VERSION ""

NS_ :

BS_:

BU_: XXX t _ e f S c a I i

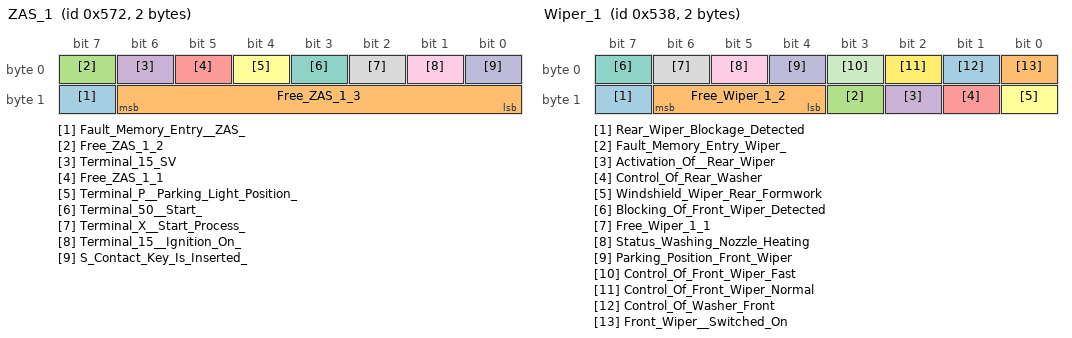
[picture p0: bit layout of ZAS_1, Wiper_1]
BO_ 1394 ZAS_1: 2 XXX
 SG_ Fault_Memory_Entry__ZAS_ : 15|1@1+ (1,0) [0|0] "" XXX
 SG_ Free_ZAS_1_3 : 8|7@1+ (1,0) [0|0] "" XXX
 SG_ Free_ZAS_1_2 : 7|1@1+ (1,0) [0|0] "" XXX
 SG_ Terminal_15_SV : 6|1@1+ (1,0) [0|0] "" XXX
 SG_ Free_ZAS_1_1 : 5|1@1+ (1,0) [0|0] "" XXX
 SG_ Terminal_P__Parking_Light_Position_ : 4|1@1+ (1,0) [0|0] "" XXX
 SG_ Terminal_50__Start_ : 3|1@1+ (1,0) [0|0] "" XXX
 SG_ Terminal_X__Start_Process_ : 2|1@1+ (1,0) [0|0] "" XXX
 SG_ Terminal_15__Ignition_On_ : 1|1@1+ (1,0) [0|0] "" XXX
 SG_ S_Contact_Key_Is_Inserted_ : 0|1@1+ (1,0) [0|0] "" XXX

BO_ 1336 Wiper_1: 2 XXX
 SG_ Rear_Wiper_Blockage_Detected : 15|1@1+ (1,0) [0|0] "" XXX
 SG_ Free_Wiper_1_2 : 12|3@1+ (1,0) [0|0] "" XXX
 SG_ Fault_Memory_Entry_Wiper_ : 11|1@1+ (1,0) [0|0] "" XXX
 SG_ Activation_Of__Rear_Wiper : 10|1@1+ (1,0) [0|0] "" XXX
 SG_ Control_Of_Rear_Washer : 9|1@1+ (1,0) [0|0] "" XXX
 SG_ Windshield_Wiper_Rear_Formwork : 8|1@1+ (1,0) [0|0] "" XXX
 SG_ Blocking_Of_Front_Wiper_Detected : 7|1@1+ (1,0) [0|0] "" XXX
 SG_ Free_Wiper_1_1 : 6|1@1+ (1,0) [0|0] "" XXX
 SG_ Status_Washing_Nozzle_Heating : 5|1@1+ (1,0) [0|0] "" XXX
 SG_ Parking_Position_Front_Wiper : 4|1@1+ (1,0) [0|0] "" XXX
 SG_ Control_Of_Front_Wiper_Fast : 3|1@1+ (1,0) [0|0] "" XXX
 SG_ Control_Of_Front_Wiper_Normal : 2|1@1+ (1,0) [0|0] "" XXX
 SG_ Control_Of_Washer_Front : 1|1@1+ (1,0) [0|0] "" XXX
 SG_ Front_Wiper__Switched_On : 0|1@1+ (1,0) [0|0] "" XXX

BO_ 1464 Immobilizer_1: 2 XXX
 SG_ Immobilizer_Textbits : 8|8@1+ (1,0) [0|0] "" XXX
 SG_ Free_Immobilizer_1_1 : 1|7@1+ (1,0) [0|0] "" XXX
 SG_ Immobilizer_LED : 0|1@1+ (1,0) [0|0] "" XXX

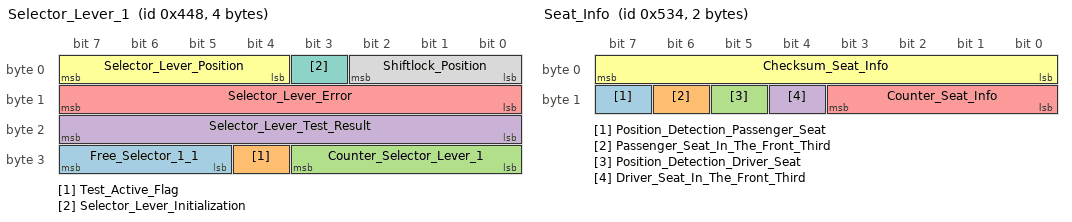
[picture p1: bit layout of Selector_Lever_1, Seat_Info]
BO_ 1096 Selector_Lever_1: 4 XXX
 SG_ Free_Selector_1_1 : 29|3@1+ (1,0) [0|0] "" XXX
 SG_ Test_Active_Flag : 28|1@1+ (1,0) [0|0] "" XXX
 SG_ Counter_Selector_Lever_1 : 24|4@1+ (1,0) [0|15] "" XXX
 SG_ Selector_Lever_Test_Result : 16|8@1+ (1,0) [0|255] "" XXX
 SG_ Selector_Lever_Error : 8|8@1+ (1,0) [0|0] "" XXX
 SG_ Selector_Lever_Position : 4|4@1+ (1,0) [0|0] "" XXX
 SG_ Selector_Lever_Initialization : 3|1@1+ (1,0) [0|0] "" XXX
 SG_ Shiftlock_Position : 0|3@1+ (1,0) [0|0] "" XXX

BO_ 1496 Installation_List_1: 8 XXX
 SG_ TV_Tuner : 63|1@1+ (1,0) [0|0] "" XXX
 SG_ DSP : 62|1@1+ (1,0) [0|0] "" XXX
 SG_ CD_Changer : 61|1@1+ (1,0) [0|0] "" XXX
 SG_ Voice_Input : 60|1@1+ (1,0) [0|0] "" XXX
 SG_ Telematics : 59|1@1+ (1,0) [0|0] "" XXX
 SG_ Navigation : 58|1@1+ (1,0) [0|0] "" XXX
 SG_ Phone : 57|1@1+ (1,0) [0|0] "" XXX
 SG_ Radio : 56|1@1+ (1,0) [0|0] "" XXX
 SG_ Multi_Media_In_Front : 55|1@1+ (1,0) [0|0] "" XXX
 SG_ Multi_Media_In_Rear : 54|1@1+ (1,0) [0|0] "" XXX
 SG_ Free_Installation_List_1_11 : 53|1@1+ (1,0) [0|0] "" XXX
 SG_ Air_Conditioning_Control_Unit_HL : 52|1@1+ (1,0) [0|0] "" XXX
 SG_ Free_Installation_List_1_10 : 50|2@1+ (1,0) [0|0] "" XXX
 SG_ Tank_Sensor : 49|1@1+ (1,0) [0|0] "" XXX
 SG_ Assistant_Driving_Lights : 48|1@1+ (1,0) [0|0] "" XXX
 SG_ Memory_Behind_Driver : 47|1@1+ (1,0) [0|0] "" XXX
 SG_ Seat_Memory_In_The_Back : 46|1@1+ (1,0) [0|0] "" XXX
 SG_ Seat_Memory_Passenger : 45|1@1+ (1,0) [0|0] "" XXX
 SG_ Trailer_Control_Unit : 44|1@1+ (1,0) [0|0] "" XXX
 SG_ Energy_Management : 43|1@1+ (1,0) [0|0] "" XXX
 SG_ Wiper_Module : 42|1@1+ (1,0) [0|0] "" XXX
 SG_ EZS___Kessy__Comfort_ : 41|1@1+ (1,0) [0|0] "" XXX
 SG_ Convertable_Top_Control : 40|1@1+ (1,0) [0|0] "" XXX
 SG_ Heater : 39|1@1+ (1,0) [0|0] "" XXX
 SG_ Free_Installation_List_1_9 : 38|1@1+ (1,0) [0|0] "" XXX
 SG_ Parking_Aid : 37|1@1+ (1,0) [0|0] "" XXX
 SG_ Air_Conditioning_Control_Unit_Comfort : 36|1@1+ (1,0) [0|0] "" XXX
 SG_ Gateway : 35|1@1+ (1,0) [0|0] "" XXX
 SG_ Steering_Column_Module : 34|1@1+ (1,0) [0|0] "" XXX
 SG_ Tire_Pressure : 33|1@1+ (1,0) [0|0] "" XXX
 SG_ Instrument_Cluster_Comfort : 32|1@1+ (1,0) [0|0] "" XXX
 SG_ Roof_Module : 31|1@1+ (1,0) [0|0] "" XXX
 SG_ Memory : 30|1@1+ (1,0) [0|0] "" XXX
 SG_ TSG_HR : 29|1@1+ (1,0) [0|0] "" XXX
 SG_ TSG_HL : 28|1@1+ (1,0) [0|0] "" XXX
 SG_ TSG_BT : 27|1@1+ (1,0) [0|0] "" XXX
 SG_ TSG_FT : 26|1@1+ (1,0) [0|0] "" XXX
 SG_ ZKE : 25|1@1+ (1,0) [0|0] "" XXX
 SG_ BSG_Comfort : 24|1@1+ (1,0) [0|0] "" XXX
 SG_ Free_Installation_List_1_8 : 19|5@1+ (1,0) [0|0] "" XXX
 SG_ Stable_Decoupling : 18|1@1+ (1,0) [0|0] "" XXX
 SG_ Selector_Lever : 17|1@1+ (1,0) [0|0] "" XXX
 SG_ Battery_Manager : 16|1@1+ (1,0) [0|0] "" XXX
 SG_ Damper_SG : 15|1@1+ (1,0) [0|0] "" XXX
 SG_ Leveling : 14|1@1+ (1,0) [0|0] "" XXX
 SG_ EZS___Kessy__Drive_ : 13|1@1+ (1,0) [0|0] "" XXX
 SG_ Brake_Booster : 12|1@1+ (1,0) [0|0] "" XXX
 SG_ Power_Steering : 11|1@1+ (1,0) [0|0] "" XXX
 SG_ Station_Wagon_Drive : 10|1@1+ (1,0) [0|0] "" XXX
 SG_ Injection_Pump : 9|1@1+ (1,0) [0|0] "" XXX
 SG_ Steering_Angle : 8|1@1+ (1,0) [0|0] "" XXX
 SG_ Four_Wheel : 7|1@1+ (1,0) [0|0] "" XXX
 SG_ BSG_Drive : 6|1@1+ (1,0) [0|0] "" XXX
 SG_ ADR : 5|1@1+ (1,0) [0|0] "" XXX
 SG_ Airbag : 4|1@1+ (1,0) [0|0] "" XXX
 SG_ Climatronic_Drive : 3|1@1+ (1,0) [0|0] "" XXX
 SG_ ABS : 2|1@1+ (1,0) [0|0] "" XXX
 SG_ Gearbox_Control_Unit : 1|1@1+ (1,0) [0|0] "" XXX
 SG_ Engine_Control_Unit : 0|1@1+ (1,0) [0|0] "" XXX

BO_ 1488 Systeminfo_1: 6 XXX
 SG_ CAN_Stand_4_1_Drive_Data_Hau : 44|4@1+ (1,0) [0|15] "" XXX
 SG_ CAN_Stand_4_1_Drive_Data_Neb : 40|4@1+ (1,0) [0|15] "" XXX
 SG_ CAN_Stand_4_1_Comfort_Data_Hau : 36|4@1+ (1,0) [0|15] "" XXX
 SG_ CAN_Stand_4_1_Comfort_Data_Neb : 32|4@1+ (1,0) [0|15] "" XXX
 SG_ Free_System_Info_1_6 : 30|1@1+ (1,0) [0|0] "" XXX
 SG_ Four_Day : 29|1@1+ (1,0) [0|0] "" XXX
 SG_ Right_Hand_Drive : 28|1@1+ (1,0) [0|0] "" XXX
 SG_ Vehicle_Index : 24|4@1+ (1,0) [0|0] "" XXX
 SG_ Vehicle_Generation : 20|4@1+ (1,0) [0|15] "" XXX
 SG_ Vehicle_Derivative : 16|4@1+ (1,0) [0|15] "" XXX
 SG_ Vehicle_Brand_2 : 12|4@1+ (1,0) [0|15] "" XXX
 SG_ Vehicle_Class : 8|4@1+ (1,0) [0|15] "" XXX
 SG_ Installation_Information_Valid : 7|1@1+ (1,0) [0|0] "" XXX
 SG_ CAN_Infotainment_Installed : 6|1@1+ (1,0) [0|0] "" XXX
 SG_ CAN_Infotainment_In_Diagnosis : 5|1@1+ (1,0) [0|0] "" XXX
 SG_ Sleep_CAN_Infotainment : 4|1@1+ (1,0) [0|0] "" XXX
 SG_ CAN_Comfort_In_Diagnosis : 3|1@1+ (1,0) [0|0] "" XXX
 SG_ Sleep_CAN_Comfort : 2|1@1+ (1,0) [0|0] "" XXX
 SG_ CAN_Drive_in_Diagnose : 1|1@1+ (1,0) [0|0] "" XXX
 SG_ CAN_External_Connected : 0|1@1+ (1,0) [0|0] "" XXX

BO_ 268 Slave_1: 8 XXX
 SG_ Delta_Reduced_Target_Torque : 48|1@1+ (1,0) [0|0] "" XXX
 SG_ Delta_Throttle_Angle : 32|16@1+ (1,0) [0|0] "" XXX
 SG_ Free_Slave_1_1 : 25|7@1+ (1,0) [0|0] "" XXX
 SG_ Delta_Firing_Angle_Output : 24|1@1+ (1,0) [0|0] "" XXX
 SG_ Ubat_Freigabe_DVE__Slave_ : 23|1@1+ (1,0) [0|0] "" XXX
 SG_ Throttle_Valve_Setpoint_Limitation : 22|1@1+ (1,0) [0|0] "" XXX
 SG_ Injection_Ban_Learn_Slave : 21|1@1+ (1,0) [0|0] "" XXX
 SG_ Master_Recognized__Slave_ : 20|1@1+ (1,0) [0|0] "" XXX
 SG_ Moment_Output_Error : 19|1@1+ (1,0) [0|0] "" XXX
 SG_ Gearbox_Torque_Error : 18|1@1+ (1,0) [0|0] "" XXX
 SG_ Brake_Message_Error : 17|1@1+ (1,0) [0|0] "" XXX
 SG_ Indexed_Actual_Torque_Slave : 0|16@1+ (0.0015259,0) [0|99.998] "%" XXX
 SG_ Brake_Message_Timeout : 0|1@1+ (1,0) [0|0] "" XXX

BO_ 1332 Seat_Info: 2 XXX
 SG_ Position_Detection_Passenger_Seat : 15|1@1+ (1,0) [0|0] "" XXX
 SG_ Passenger_Seat_In_The_Front_Third : 14|1@1+ (1,0) [0|0] "" XXX
 SG_ Position_Detection_Driver_Seat : 13|1@1+ (1,0) [0|0] "" XXX
 SG_ Driver_Seat_In_The_Front_Third : 12|1@1+ (1,0) [0|0] "" XXX
 SG_ Counter_Seat_Info : 8|4@1+ (1,0) [0|15] "" XXX
 SG_ Checksum_Seat_Info : 0|8@1+ (1,0) [0|0] "" XXX

BO_ 1810 PSG_3: 2 XXX
 SG_ Self_Test_Result : 0|16@1+ (1,0) [0|0] "" XXX

BO_ 1298 PSG_2: 8 XXX
 SG_ RAM_Content_4 : 48|16@1+ (1,0) [0|0] "" XXX
 SG_ RAM_Content_3 : 32|16@1+ (1,0) [0|0] "" XXX
 SG_ RAM_Content_2 : 16|16@1+ (1,0) [0|0] "" XXX
 SG_ RAM_Content_1 : 0|16@1+ (1,0) [0|0] "" XXX

BO_ 274 PSG_1: 8 XXX
 SG_ Pump_Temperature__2_1_ : 48|16@1+ (0.0625,0) [0|4096] "K" XXX
 SG_ Pump_Temperature__3_2_2_ : 44|12@1+ (1,0) [0|0] "" XXX
 SG_ Cylinder_Counter__3_2_2_ : 43|3@1+ (1,0) [1|8] "Zaehler" XXX
 SG_ Control_Period__3_2_2_ : 32|11@1+ (0.0469,0) [0|96] "NW" XXX
 SG_ Camshaft_Speed__3_2_2_ : 20|12@1+ (4,0) [0|16380] "upm" XXX
 SG_ Pump_Status : 0|20@1+ (1,0) [0|0] "" XXX

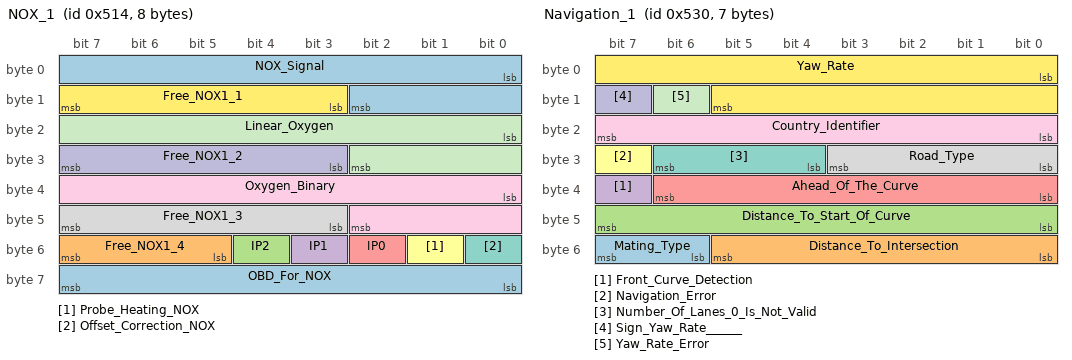
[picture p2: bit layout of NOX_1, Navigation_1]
BO_ 1300 NOX_1: 8 XXX
 SG_ OBD_For_NOX : 56|8@1+ (1,0) [0|0] "" XXX
 SG_ Free_NOX1_4 : 53|3@1+ (1,0) [0|0] "" XXX
 SG_ IP2 : 52|1@1+ (1,0) [0|0] "" XXX
 SG_ IP1 : 51|1@1+ (1,0) [0|0] "" XXX
 SG_ IP0 : 50|1@1+ (1,0) [0|0] "" XXX
 SG_ Probe_Heating_NOX : 49|1@1+ (1,0) [0|0] "" XXX
 SG_ Offset_Correction_NOX : 48|1@1+ (1,0) [0|0] "" XXX
 SG_ Free_NOX1_3 : 43|5@1+ (1,0) [0|0] "" XXX
 SG_ Oxygen_Binary : 32|11@1+ (1,-200) [-200|1847] "mV" XXX
 SG_ Free_NOX1_2 : 27|5@1+ (1,0) [0|0] "" XXX
 SG_ Linear_Oxygen : 16|11@1+ (1,0) [0|2047] "1000/Lambd" XXX
 SG_ Free_NOX1_1 : 11|5@1+ (1,0) [0|0] "" XXX
 SG_ NOX_Signal : 0|11@1+ (1,0) [0|2047] "ppm" XXX

BO_ 1424 Level_1: 6 XXX
 SG_ Loading_Condition : 40|8@1+ (1,0) [0|253] "Zuladung" XXX
 SG_ Fault_Memory_Entry_Level__1 : 39|1@1+ (1,0) [0|0] "" XXX
 SG_ System_Status_Level_1 : 38|1@1+ (1,0) [0|0] "" XXX
 SG_ Reserve_Vehicle_Type : 37|1@1+ (1,0) [0|0] "" XXX
 SG_ Vehicle_Type_Level : 36|1@1+ (1,0) [0|0] "" XXX
 SG_ Text_Bits_Level_1 : 32|4@1+ (1,0) [0|0] "" XXX
 SG_ HL_Adjustment : 31|1@1+ (1,0) [0|0] "" XXX
 SG_ HR_Adjustment : 30|1@1+ (1,0) [0|0] "" XXX
 SG_ VL_Adjustment : 29|1@1+ (1,0) [0|0] "" XXX
 SG_ VR_Adjustment : 28|1@1+ (1,0) [0|0] "" XXX
 SG_ Lowering_Vehicle : 27|1@1+ (1,0) [0|0] "" XXX
 SG_ Raising_Vehicle : 26|1@1+ (1,0) [0|0] "" XXX
 SG_ Adjustment_Active : 25|1@1+ (1,0) [0|0] "" XXX
 SG_ Compressor_Run_Shortly : 24|1@1+ (1,0) [0|0] "" XXX
 SG_ Free_Level_1_5 : 23|1@1+ (1,0) [0|0] "" XXX
 SG_ Push_Button_Level : 22|1@1+ (1,0) [0|0] "" XXX
 SG_ Park_Level : 21|1@1+ (1,0) [0|0] "" XXX
 SG_ Intermediate_Level : 20|1@1+ (1,0) [0|0] "" XXX
 SG_ Static_Level : 16|4@1+ (1,0) [0|0] "" XXX
 SG_ MSG_Restriction : 15|1@1+ (1,0) [0|0] "" XXX
 SG_ ESP_Influence : 14|1@1+ (1,0) [0|0] "" XXX
 SG_ Warning_Lamp_Level_1 : 13|1@1+ (1,0) [0|0] "" XXX
 SG_ Free_Level_1_1 : 12|1@1+ (1,0) [0|0] "" XXX
 SG_ Level_1_Counter : 8|4@1+ (1,0) [0|15] "Zaehler" XXX
 SG_ Checksum_Level_1 : 0|8@1+ (1,0) [0|0] "" XXX

BO_ 1328 Navigation_1: 7 XXX
 SG_ Mating_Type : 54|2@1+ (1,0) [0|3] "" XXX
 SG_ Distance_To_Intersection : 48|6@1+ (5,0) [0|315] "m" XXX
 SG_ Distance_To_Start_Of_Curve : 40|8@1+ (1,0) [0|255] "m" XXX
 SG_ Front_Curve_Detection : 39|1@1+ (1,0) [0|0] "" XXX
 SG_ Ahead_Of_The_Curve : 32|7@1+ (50,0) [0|6350] "m" XXX
 SG_ Navigation_Error : 31|1@1+ (1,0) [0|0] "" XXX
 SG_ Number_Of_Lanes_0_Is_Not_Valid : 28|3@1+ (1,0) [1|7] "" XXX
 SG_ Road_Type : 24|4@1+ (1,0) [0|15] "" XXX
 SG_ Country_Identifier : 16|8@1+ (1,0) [0|0] "" XXX
 SG_ Sign_Yaw_Rate______ : 15|1@1+ (1,0) [0|0] "" XXX
 SG_ Yaw_Rate_Error : 14|1@1+ (1,0) [0|0] "" XXX
 SG_ Yaw_Rate : 0|14@1+ (0.01,0) [0|100] "deg/sek" XXX

BO_ 1792 MSG_3: 3 XXX
 SG_ MSG_Configuration : 16|8@1+ (1,0) [0|0] "" XXX
 SG_ Location_Of_The_OT_Pulse : 0|16@1+ (0.01172,-384) [-384|384] "KW" XXX

BO_ 1280 MSG_2: 8 XXX
 SG_ RAM_Address_4 : 48|16@1+ (1,0) [0|0] "" XXX
 SG_ RAM_Address_3 : 32|16@1+ (1,0) [0|0] "" XXX
 SG_ RAM_Address_2 : 16|16@1+ (1,0) [0|0] "" XXX
 SG_ Ram_Address_1 : 0|16@1+ (1,0) [0|0] "" XXX

BO_ 256 MSG_1: 8 XXX
 SG_ Crankshaft_Speed__3_2_2_ : 56|8@1+ (1,0) [0|0] "" XXX
 SG_ Should_Funding_Start_KW__3_2_2_ : 40|16@1+ (0.01172,-384) [-384|384] "KW" XXX
 SG_ Should_Funding_Start_NW__3_2_2_ : 28|12@1+ (0.01172,0) [0|768] "degNW" XXX
 SG_ Should_Be_Preinjection : 16|12@1+ (1,0) [0|0] "" XXX
 SG_ Target_Injection_Quantity : 0|16@1+ (0.03125,0) [0|2047] "mg/H" XXX

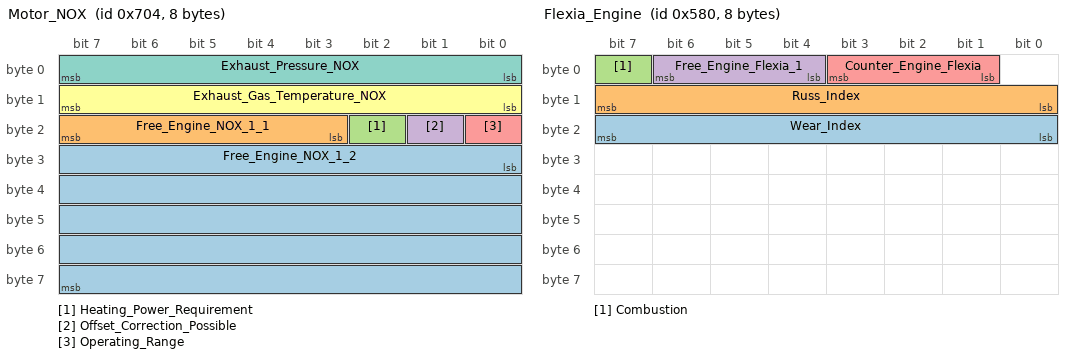
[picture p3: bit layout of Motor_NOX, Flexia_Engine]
BO_ 1796 Motor_NOX: 8 XXX
 SG_ Free_Engine_NOX_1_2 : 24|40@1+ (1,0) [0|0] "" XXX
 SG_ Free_Engine_NOX_1_1 : 19|5@1+ (1,0) [0|0] "" XXX
 SG_ Heating_Power_Requirement : 18|1@1+ (1,0) [0|0] "" XXX
 SG_ Offset_Correction_Possible : 17|1@1+ (1,0) [0|0] "" XXX
 SG_ Operating_Range : 16|1@1+ (1,0) [0|0] "" XXX
 SG_ Exhaust_Gas_Temperature_NOX : 8|8@1+ (5,-40) [-40|1230] "C" XXX
 SG_ Exhaust_Pressure_NOX : 0|8@1+ (5,600) [600|1870] "mbar" XXX

BO_ 900 Engine_Moments: 8 XXX
 SG_ Moments_Inaccurate_Moment : 35|2@1+ (1,0) [0|0] "" XXX

BO_ 1408 Flexia_Engine: 8 XXX
 SG_ Wear_Index : 16|8@1+ (1,0) [0|254] "" XXX
 SG_ Russ_Index : 8|8@1+ (1,0) [0|254] "" XXX
 SG_ Combustion : 7|1@1+ (1,0) [0|0] "" XXX
 SG_ Free_Engine_Flexia_1 : 4|3@1+ (1,0) [0|0] "" XXX
 SG_ Counter_Engine_Flexia : 1|3@1+ (1,0) [0|15] "" XXX

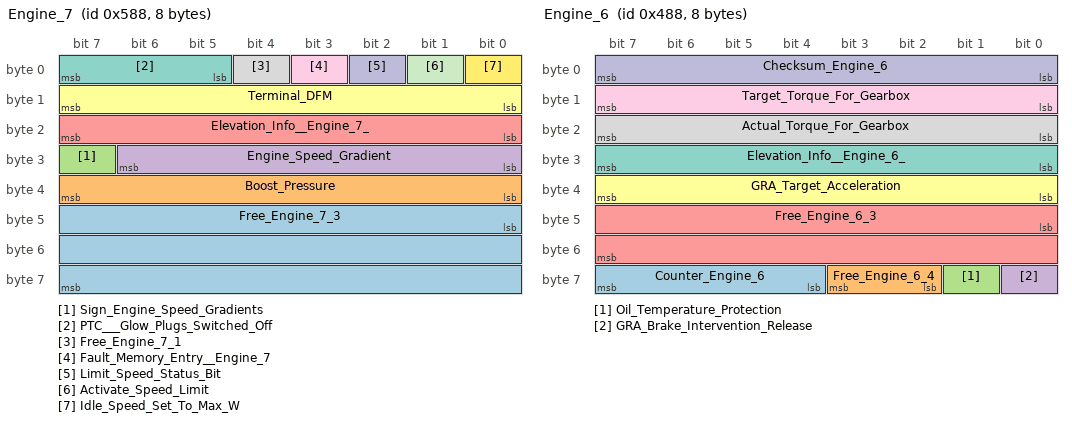
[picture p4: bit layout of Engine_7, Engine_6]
BO_ 1416 Engine_7: 8 XXX
 SG_ Free_Engine_7_3 : 40|24@1+ (1,0) [0|0] "" XXX
 SG_ Boost_Pressure : 32|8@1+ (0.01,0) [0|2.54] "bar" XXX
 SG_ Sign_Engine_Speed_Gradients : 31|1@1+ (1,0) [0|0] "" XXX
 SG_ Engine_Speed_Gradient : 24|7@1+ (1,0) [0|126] "U/min" XXX
 SG_ Elevation_Info__Engine_7_ : 16|8@1+ (0.00787,0) [0|2] "" XXX
 SG_ Terminal_DFM : 8|8@1+ (0.4,0) [0|101.6] "%" XXX
 SG_ PTC___Glow_Plugs_Switched_Off : 5|3@1+ (1,0) [0|0] "" XXX
 SG_ Free_Engine_7_1 : 4|1@1+ (1,0) [0|0] "" XXX
 SG_ Fault_Memory_Entry__Engine_7 : 3|1@1+ (1,0) [0|0] "" XXX
 SG_ Limit_Speed_Status_Bit : 2|1@1+ (1,0) [0|0] "" XXX
 SG_ Activate_Speed_Limit : 1|1@1+ (1,0) [0|0] "" XXX
 SG_ Idle_Speed_Set_To_Max_W : 0|1@1+ (1,0) [0|0] "" XXX

BO_ 1160 Engine_6: 8 XXX
 SG_ Counter_Engine_6 : 60|4@1+ (1,0) [0|15] "" XXX
 SG_ Free_Engine_6_4 : 58|2@1+ (1,0) [0|0] "" XXX
 SG_ Oil_Temperature_Protection : 57|1@1+ (1,0) [0|0] "" XXX
 SG_ GRA_Brake_Intervention_Release : 56|1@1+ (1,0) [0|0] "" XXX
 SG_ Free_Engine_6_3 : 40|16@1+ (1,0) [0|0] "" XXX
 SG_ GRA_Target_Acceleration : 32|8@1+ (0.024,-3.984) [-3.984|2.112] "m/s2" XXX
 SG_ Elevation_Info__Engine_6_ : 24|8@1+ (0.00787,0) [0|2] "" XXX
 SG_ Actual_Torque_For_Gearbox : 16|8@1+ (0.39,0) [0|99] "MDI" XXX
 SG_ Target_Torque_For_Gearbox : 8|8@1+ (0.39,0) [0|99] "MDI" XXX
 SG_ Checksum_Engine_6 : 0|8@1+ (1,0) [0|0] "" XXX

BO_ 1152 Engine_5: 8 XXX
 SG_ Checksum_Engine_5 : 56|8@1+ (1,0) [0|0] "" XXX
 SG_ Engine_Text_Bits__4_1_ : 52|4@1+ (1,0) [0|0] "" XXX
 SG_ Double_Moments : 51|1@1+ (1,0) [0|0] "" XXX
 SG_ GRA_Main_Switch : 50|1@1+ (1,0) [0|0] "" XXX
 SG_ Starter_Trace : 49|1@1+ (1,0) [0|0] "" XXX
 SG_ Starter_Release : 48|1@1+ (1,0) [0|0] "" XXX
 SG_ Climate_Pressure_Signal__Engine_5_ : 40|8@1+ (0.2,0) [0|50.8] "bar" XXX
 SG_ Radiator_Fan_Control : 32|8@1+ (0.4,0) [0|101.6] "%" XXX
 SG_ Consumption_Overflow : 31|1@1+ (1,0) [0|0] "" XXX
 SG_ Fuel_Consumption_Signal : 16|15@1+ (1,0) [0|32767] "ul" XXX
 SG_ Air_Conditioning_Compressor_Power_Reduction : 15|1@1+ (1,0) [0|0] "" XXX
 SG_ Map_Cooling : 14|1@1+ (1,0) [0|0] "" XXX
 SG_ Air_Conditioning_Compressor_From__Engine_5 : 13|1@1+ (1,0) [0|0] "" XXX
 SG_ CAT_Warning : 12|1@1+ (1,0) [0|0] "" XXX
 SG_ OBD_2_Lamp : 11|1@1+ (1,0) [0|0] "" XXX
 SG_ E_Gas_Lamp : 10|1@1+ (1,0) [0|0] "" XXX
 SG_ Glow_Plug_Lamp__Motor_5_ : 9|1@1+ (1,0) [0|0] "" XXX
 SG_ Charge_Control_Lamp : 8|1@1+ (1,0) [0|0] "" XXX

BO_ 896 Engine_3: 8 XXX
 SG_ Engine_Desired_Speed : 48|8@1+ (25,0) [0|6350] "U/min" XXX
 SG_ Engine_Speed_Manipulation : 40|8@1+ (0.392,0) [0|100] "%" XXX
 SG_ No_Start_Stop : 39|1@1+ (1,0) [0|0] "" XXX
 SG_ No_Gas : 38|1@1+ (1,0) [0|0] "" XXX
 SG_ Reserved_Engine_3_1 : 37|1@1+ (1,0) [0|0] "" XXX
 SG_ Sign_Wheel_Desired_Torque : 36|1@1+ (1,0) [0|0] "" XXX
 SG_ Wheel_Desired_Moment : 24|12@1+ (0.39,0) [0|1597] "MDI" XXX
 SG_ Accelerator_Pedal_Raw_Signal : 16|8@1+ (0.4,0) [0|101.6] "%" XXX
 SG_ Intake : 8|8@1+ (0.75,-48) [-48|142.5] "" XXX
 SG_ Intake_Air_Temperature_Error_Status : 7|1@1+ (1,0) [0|0] "" XXX
 SG_ Engine_Control_Unit_Locked : 6|1@1+ (1,0) [0|0] "" XXX
 SG_ Throttle_Valve_Angle_Inaccurate : 5|1@1+ (1,0) [0|0] "" XXX
 SG_ Accelerator_Pedal_Value_Inaccurate__Engine_3 : 4|1@1+ (1,0) [0|0] "" XXX
 SG_ Free_Engine_3_1 : 3|1@1+ (1,0) [0|0] "" XXX
 SG_ Engine_Desired_Speed_Priority : 2|1@1+ (1,0) [0|0] "" XXX
 SG_ Engine_Overtemperature_Protection__Engine_3 : 1|1@1+ (1,0) [0|0] "" XXX
 SG_ Early_Warning : 0|1@1+ (1,0) [0|0] "" XXX
 SG_ Throttle_Valve_Potentiometer : 56|8@1+ (0.4,0) [0|101.6] "%" XXX

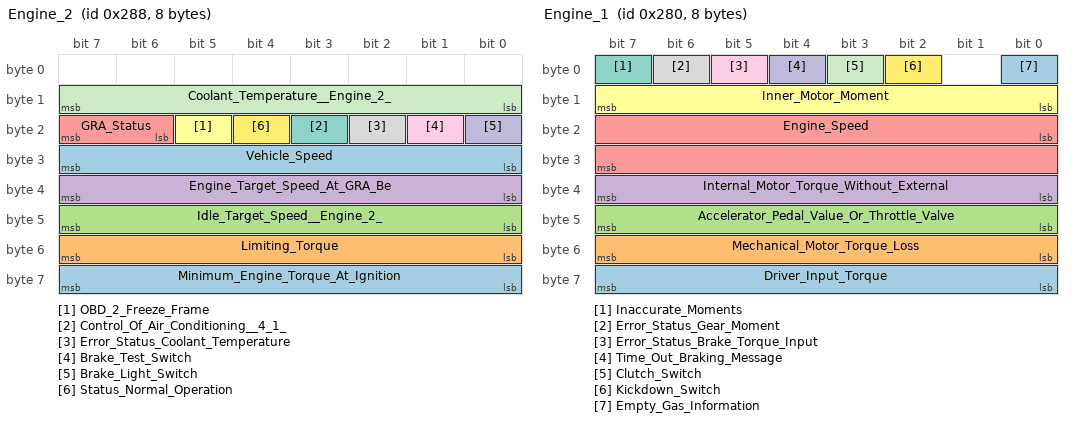
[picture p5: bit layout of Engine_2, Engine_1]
BO_ 648 Engine_2: 8 XXX
 SG_ Minimum_Engine_Torque_At_Ignition : 56|8@1+ (0.39,0) [0|99] "MDI" XXX
 SG_ Limiting_Torque : 48|8@1+ (0.39,0) [0|99] "MDI" XXX
 SG_ Idle_Target_Speed__Engine_2_ : 40|8@1+ (10,0) [0|2540] "U/min" XXX
 SG_ Engine_Target_Speed_At_GRA_Be : 32|8@1+ (1.28,0) [0|325] "km/h" XXX
 SG_ GRA_Status : 22|2@1+ (1,0) [0|0] "" XXX
 SG_ OBD_2_Freeze_Frame : 21|1@1+ (1,0) [0|0] "" XXX
 SG_ Control_Of_Air_Conditioning__4_1_ : 19|1@1+ (1,0) [0|0] "" XXX
 SG_ Error_Status_Coolant_Temperature : 18|1@1+ (1,0) [0|0] "" XXX
 SG_ Brake_Test_Switch : 17|1@1+ (1,0) [0|0] "" XXX
 SG_ Brake_Light_Switch : 16|1@1+ (1,0) [0|0] "" XXX
 SG_ Coolant_Temperature__Engine_2_ : 8|8@1+ (0.75,-48) [-48|142.5] "" XXX
 SG_ Status_Normal_Operation : 20|1@1+ (1,0) [0|0] "" XXX
 SG_ Vehicle_Speed : 24|8@1+ (1.28,0) [0|325] "km/h" XXX

BO_ 640 Engine_1: 8 XXX
 SG_ Driver_Input_Torque : 56|8@1+ (0.39,0) [0|99] "MDI" XXX
 SG_ Mechanical_Motor_Torque_Loss : 48|8@1+ (0.39,0) [0|99] "MDI" XXX
 SG_ Accelerator_Pedal_Value_Or_Throttle_Valve : 40|8@1+ (0.4,0) [0|101.6] "%" XXX
 SG_ Internal_Motor_Torque_Without_External : 32|8@1+ (0.39,0) [0|99] "MDI" XXX
 SG_ Engine_Speed : 16|16@1+ (0.25,0) [0|16256] "U/min" XXX
 SG_ Inner_Motor_Moment : 8|8@1+ (0.39,0) [0|99] "MDI" XXX
 SG_ Inaccurate_Moments : 7|1@1+ (1,0) [0|0] "" XXX
 SG_ Error_Status_Gear_Moment : 6|1@1+ (1,0) [0|0] "" XXX
 SG_ Error_Status_Brake_Torque_Input : 5|1@1+ (1,0) [0|0] "" XXX
 SG_ Time_Out_Braking_Message : 4|1@1+ (1,0) [0|0] "" XXX
 SG_ Clutch_Switch : 3|1@1+ (1,0) [0|0] "" XXX
 SG_ Kickdown_Switch : 2|1@1+ (1,0) [0|0] "" XXX
 SG_ Empty_Gas_Information : 0|1@1+ (1,0) [0|0] "" XXX

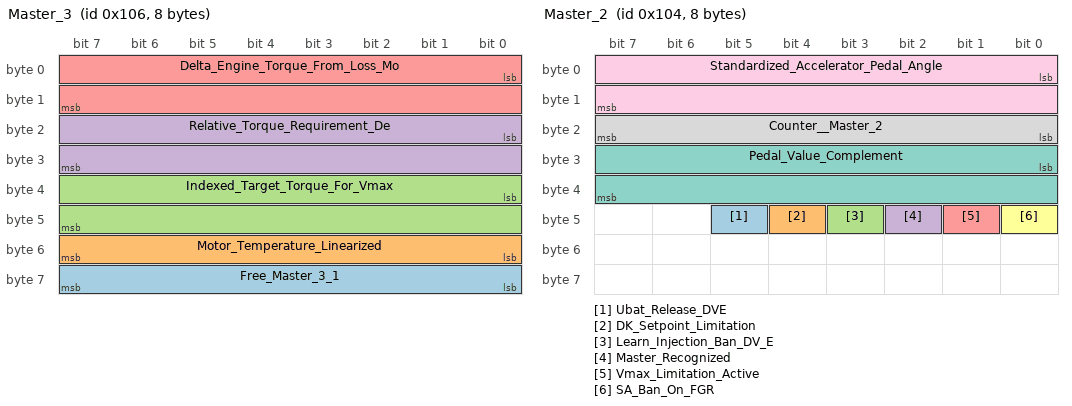
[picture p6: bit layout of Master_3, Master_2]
BO_ 262 Master_3: 8 XXX
 SG_ Free_Master_3_1 : 56|8@1+ (1,0) [0|0] "" XXX
 SG_ Motor_Temperature_Linearized : 48|8@1+ (0.75,-48) [-48|143.25] "" XXX
 SG_ Indexed_Target_Torque_For_Vmax : 32|16@1+ (0.0015259,0) [0|100] "%" XXX
 SG_ Relative_Torque_Requirement_De : 16|16@1+ (0.003052,0) [0|200] "%" XXX
 SG_ Delta_Engine_Torque_From_Loss_Mo : 0|16@1+ (0.003052,-100) [-100|100] "%" XXX

BO_ 260 Master_2: 8 XXX
 SG_ Ubat_Release_DVE : 45|1@1+ (1,0) [0|0] "" XXX
 SG_ DK_Setpoint_Limitation : 44|1@1+ (1,0) [0|0] "" XXX
 SG_ Learn_Injection_Ban_DV_E : 43|1@1+ (1,0) [0|0] "" XXX
 SG_ Master_Recognized : 42|1@1+ (1,0) [0|0] "" XXX
 SG_ Vmax_Limitation_Active : 41|1@1+ (1,0) [0|0] "" XXX
 SG_ SA_Ban_On_FGR : 40|1@1+ (1,0) [0|0] "" XXX
 SG_ Pedal_Value_Complement : 24|16@1+ (1,0) [0|0] "" XXX
 SG_ Counter__Master_2 : 16|8@1+ (1,0) [0|255] "" XXX
 SG_ Standardized_Accelerator_Pedal_Angle : 0|16@1+ (0.001526,0) [0|100] "%" XXX

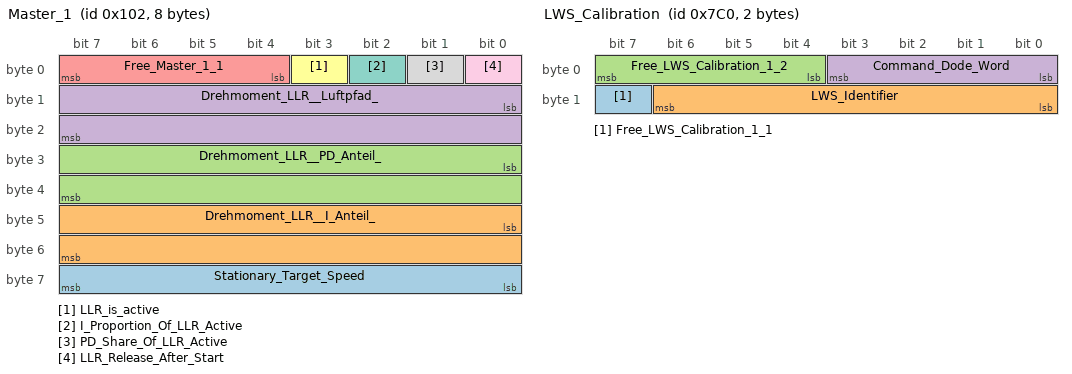
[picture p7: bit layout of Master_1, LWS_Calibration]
BO_ 258 Master_1: 8 XXX
 SG_ Stationary_Target_Speed : 56|8@1+ (10,0) [0|2550] "Umin" XXX
 SG_ Drehmoment_LLR__I_Anteil_ : 40|16@1+ (0.003052,-100) [-100|100] "%" XXX
 SG_ Drehmoment_LLR__PD_Anteil_ : 24|16@1+ (0.003052,-100) [-100|100] "%" XXX
 SG_ Drehmoment_LLR__Luftpfad_ : 8|16@1+ (0.003052,-100) [-100|100] "%" XXX
 SG_ Free_Master_1_1 : 4|4@1+ (1,0) [0|0] "" XXX
 SG_ LLR_is_active : 3|1@1+ (1,0) [0|0] "" XXX
 SG_ I_Proportion_Of_LLR_Active : 2|1@1+ (1,0) [0|0] "" XXX
 SG_ PD_Share_Of_LLR_Active : 1|1@1+ (1,0) [0|0] "" XXX
 SG_ LLR_Release_After_Start : 0|1@1+ (1,0) [0|0] "" XXX

BO_ 1984 LWS_Calibration: 2 XXX
 SG_ Free_LWS_Calibration_1_1 : 15|1@1+ (1,0) [0|0] "" XXX
 SG_ LWS_Identifier : 8|7@1+ (1,0) [0|0] "" XXX
 SG_ Free_LWS_Calibration_1_2 : 4|4@1+ (1,0) [0|0] "" XXX
 SG_ Command_Dode_Word : 0|4@1+ (1,0) [0|0] "" XXX

BO_ 1986 Steering_Angle_Init: 4 XXX
 SG_ Coding_Bytes : 8|24@1+ (1,0) [0|0] "" XXX
 SG_ Identifier_For_LWS_Init : 0|8@1+ (1,0) [0|0] "" XXX

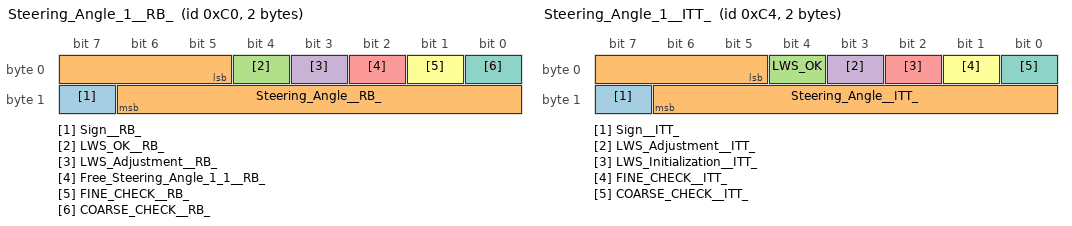
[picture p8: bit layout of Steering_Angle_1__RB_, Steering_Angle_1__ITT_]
BO_ 192 Steering_Angle_1__RB_: 2 XXX
 SG_ Sign__RB_ : 15|1@1+ (1,0) [0|0] "" XXX
 SG_ Steering_Angle__RB_ : 5|10@1+ (2.5,-720) [-720|720] "" XXX
 SG_ LWS_OK__RB_ : 4|1@1+ (1,0) [0|0] "" XXX
 SG_ LWS_Adjustment__RB_ : 3|1@1+ (1,0) [0|0] "" XXX
 SG_ Free_Steering_Angle_1_1__RB_ : 2|1@1+ (1,0) [0|0] "" XXX
 SG_ FINE_CHECK__RB_ : 1|1@1+ (1,0) [0|0] "" XXX
 SG_ COARSE_CHECK__RB_ : 0|1@1+ (1,0) [0|0] "" XXX

BO_ 196 Steering_Angle_1__ITT_: 2 XXX
 SG_ Sign__ITT_ : 15|1@1+ (1,0) [0|0] "" XXX
 SG_ Steering_Angle__ITT_ : 5|10@1+ (1.5,-768) [-768|766.5] "" XXX
 SG_ LWS_OK : 4|1@1+ (1,0) [0|0] "" XXX
 SG_ LWS_Adjustment__ITT_ : 3|1@1+ (1,0) [0|0] "" XXX
 SG_ LWS_Initialization__ITT_ : 2|1@1+ (1,0) [0|0] "" XXX
 SG_ FINE_CHECK__ITT_ : 1|1@1+ (1,0) [0|0] "" XXX
 SG_ COARSE_CHECK__ITT_ : 0|1@1+ (1,0) [0|0] "" XXX

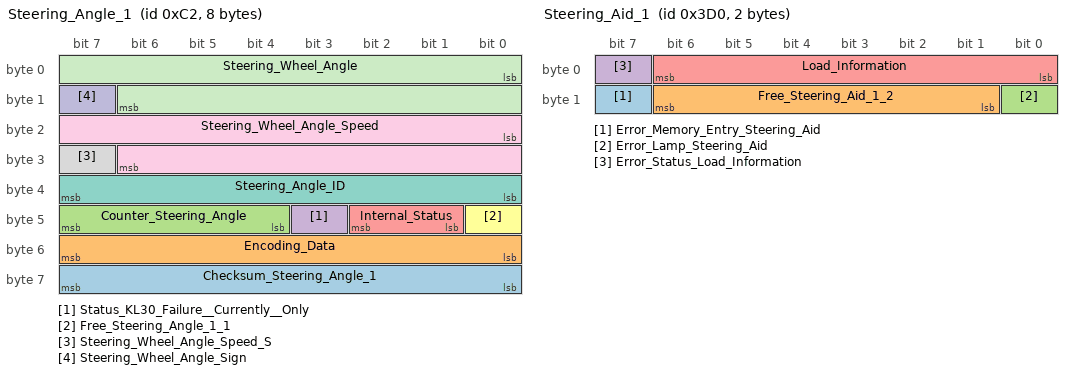
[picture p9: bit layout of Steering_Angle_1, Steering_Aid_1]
BO_ 194 Steering_Angle_1: 8 XXX
 SG_ Checksum_Steering_Angle_1 : 56|8@1+ (1,0) [0|0] "" XXX
 SG_ Encoding_Data : 48|8@1+ (1,0) [0|0] "" XXX
 SG_ Counter_Steering_Angle : 44|4@1+ (1,0) [0|15] "" XXX
 SG_ Status_KL30_Failure__Currently__Only : 43|1@1+ (1,0) [0|0] "" XXX
 SG_ Internal_Status : 41|2@1+ (1,0) [0|0] "" XXX
 SG_ Free_Steering_Angle_1_1 : 40|1@1+ (1,0) [0|0] "" XXX
 SG_ Steering_Angle_ID : 32|8@1+ (1,0) [0|0] "" XXX
 SG_ Steering_Wheel_Angle_Speed_S : 31|1@1+ (1,0) [0|0] "" XXX
 SG_ Steering_Wheel_Angle_Speed : 16|15@1+ (0.04375,0) [0|1433.6] "Grad/Sek" XXX
 SG_ Steering_Wheel_Angle_Sign : 15|1@1+ (1,0) [0|0] "" XXX
 SG_ Steering_Wheel_Angle : 0|15@1+ (0.04375,0) [0|1433.6] "Grad" XXX

BO_ 1502 Steering_Aid_Error: 7 XXX
 SG_ Workshop_Code : 48|8@1+ (1,0) [0|0] "" XXX
 SG_ Multiplex_Signal : 45|3@1+ (1,0) [0|7] "" XXX
 SG_ Steering_Air_Sendor_Coding : 44|1@1+ (1,0) [0|0] "" XXX
 SG_ Characteristic_Coding_Of_Steering_Aid : 40|4@1+ (1,0) [0|15] "Kennlinie" XXX
 SG_ Read_Encoder_From_Steering_Memory : 39|1@1+ (1,0) [0|0] "" XXX
 SG_ Read_Combi_Instr_Memory : 38|1@1+ (1,0) [0|0] "" XXX
 SG_ Read_Controller_Memory : 37|1@1+ (1,0) [0|0] "" XXX
 SG_ Steering_Aid_Control_Unit_Defective : 36|1@1+ (1,0) [0|0] "" XXX
 SG_ Free_Steering_Aid_1_3 : 32|4@1+ (1,0) [0|0] "" XXX
 SG_ Free_Steering_Aid_1_4 : 30|2@1+ (1,0) [0|0] "" XXX
 SG_ Encoder_For_Steering_Wheel_CAN_Comm : 29|1@1+ (1,0) [0|0] "" XXX
 SG_ Encoder_For_Steering_Angle_CAN_Comm : 28|1@1+ (1,0) [0|0] "" XXX
 SG_ Instrument_Cluster_K_CAN_Communicate_sp : 27|1@1+ (1,0) [0|0] "" XXX
 SG_ Instrument_Cluster_K_CAN_Communicate : 26|1@1+ (1,0) [0|0] "" XXX
 SG_ Control_Unit_K_CAN_Communicate_S : 25|1@1+ (1,0) [0|0] "" XXX
 SG_ Control_Unit_No_CAN_Communicate : 24|1@1+ (1,0) [0|0] "" XXX
 SG_ Steering_Aid_Tension_Ks_According_To_Mas : 23|1@1+ (1,0) [0|0] "" XXX
 SG_ Steering_Aid_Tension_Ks_Made_To_Measure : 22|1@1+ (1,0) [0|0] "" XXX
 SG_ Steering_Aid_Voltage_Ks_According_To_S : 21|1@1+ (1,0) [0|0] "" XXX
 SG_ Steering_Aid_Tension_Ks_After : 20|1@1+ (1,0) [0|0] "" XXX
 SG_ Steering_Aid_Temperature_Protection_SP : 19|1@1+ (1,0) [0|0] "" XXX
 SG_ Steering_Aid_Temperature_Protection : 18|1@1+ (1,0) [0|0] "" XXX
 SG_ Steering_Aid_Operation_Unpl_Signal_SP : 17|1@1+ (1,0) [0|0] "" XXX
 SG_ Steering_Aid_Operation_Unpl_Signal : 16|1@1+ (1,0) [0|0] "" XXX
 SG_ Power_Steering_Sensor_K_Communicate_SP : 15|1@1+ (1,0) [0|0] "" XXX
 SG_ Power_Steering_Sensor_No_Communication : 14|1@1+ (1,0) [0|0] "" XXX
 SG_ Steering_Aid_Sensor_Defective_SP : 13|1@1+ (1,0) [0|0] "" XXX
 SG_ Steering_Aid_Sensor_Defective : 12|1@1+ (1,0) [0|0] "" XXX
 SG_ Steering_Aid_Sensor_Interruption_S : 11|1@1+ (1,0) [0|0] "" XXX
 SG_ Steering_Aid_Sensor_Interruption : 10|1@1+ (1,0) [0|0] "" XXX
 SG_ Steering_Aid_Sensor_Ks_According_To_Mass_S : 9|1@1+ (1,0) [0|0] "" XXX
 SG_ Steering_Lift_Sensor_Ks_By_Mass : 8|1@1+ (1,0) [0|0] "" XXX
 SG_ Voltage_Terminal_15_Too_Low_SP : 7|1@1+ (1,0) [0|0] "" XXX
 SG_ Voltage_Terminal_15_Too_Low : 6|1@1+ (1,0) [0|0] "" XXX
 SG_ Free_Steering_Aid_1_5 : 4|2@1+ (1,0) [0|0] "" XXX
 SG_ Voltage_Kl_30_Too_Low_SP_ : 3|1@1+ (1,0) [0|0] "" XXX
 SG_ Voltage_Kl_30_Too_Low : 2|1@1+ (1,0) [0|0] "" XXX
 SG_ Voltage_Kl_30_Too_High__sp_ : 1|1@1+ (1,0) [0|0] "" XXX
 SG_ Voltage_Kl_30_Too_High_ : 0|1@1+ (1,0) [0|0] "" XXX

BO_ 976 Steering_Aid_1: 2 XXX
 SG_ Error_Memory_Entry_Steering_Aid : 15|1@1+ (1,0) [0|0] "" XXX
 SG_ Free_Steering_Aid_1_2 : 9|6@1+ (1,0) [0|0] "" XXX
 SG_ Error_Lamp_Steering_Aid : 8|1@1+ (1,0) [0|0] "" XXX
 SG_ Error_Status_Load_Information : 7|1@1+ (1,0) [0|0] "" XXX
 SG_ Load_Information : 0|7@1+ (1,0) [0|127] "A" XXX

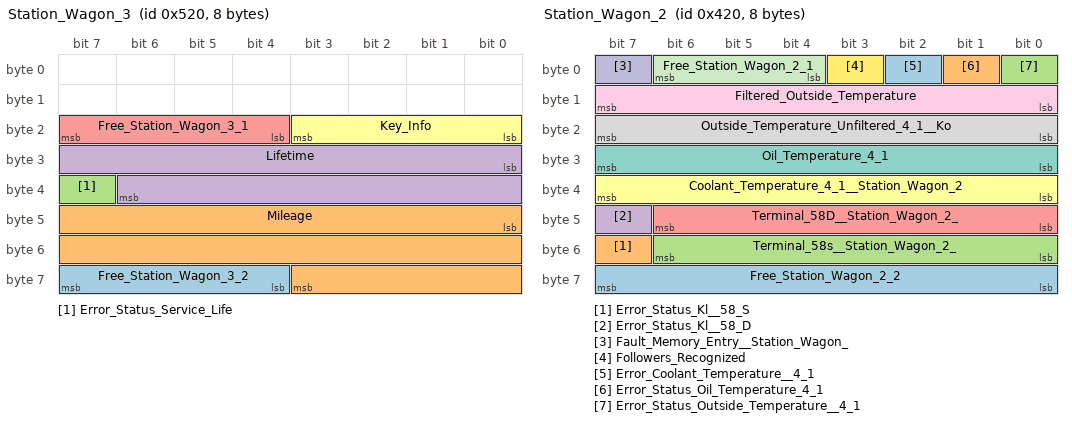
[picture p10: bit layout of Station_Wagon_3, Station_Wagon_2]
BO_ 1312 Station_Wagon_3: 8 XXX
 SG_ Free_Station_Wagon_3_2 : 60|4@1+ (1,0) [0|0] "" XXX
 SG_ Mileage : 40|20@1+ (1,0) [0|1000000] "km" XXX
 SG_ Error_Status_Service_Life : 39|1@1+ (1,0) [0|0] "" XXX
 SG_ Lifetime : 24|15@1+ (4,0) [0|131068] "sec" XXX
 SG_ Free_Station_Wagon_3_1 : 20|4@1+ (1,0) [0|0] "" XXX
 SG_ Key_Info : 16|4@1+ (1,0) [0|15] "" XXX

BO_ 1056 Station_Wagon_2: 8 XXX
 SG_ Free_Station_Wagon_2_2 : 56|8@1+ (1,0) [0|0] "" XXX
 SG_ Error_Status_Kl__58_S : 55|1@1+ (1,0) [0|0] "" XXX
 SG_ Terminal_58s__Station_Wagon_2_ : 48|7@1+ (1,0) [0|100] "%" XXX
 SG_ Error_Status_Kl__58_D : 47|1@1+ (1,0) [0|0] "" XXX
 SG_ Terminal_58D__Station_Wagon_2_ : 40|7@1+ (1,0) [0|100] "%" XXX
 SG_ Coolant_Temperature_4_1__Station_Wagon_2 : 32|8@1+ (0.75,-48) [-48|142.5] "C" XXX
 SG_ Oil_Temperature_4_1 : 24|8@1+ (1,-60) [-60|194] "C" XXX
 SG_ Outside_Temperature_Unfiltered_4_1__Ko : 16|8@1+ (0.5,-50) [-50|77] "C" XXX
 SG_ Filtered_Outside_Temperature : 8|8@1+ (0.5,-50) [-50|77] "C" XXX
 SG_ Fault_Memory_Entry__Station_Wagon_ : 7|1@1+ (1,0) [0|0] "" XXX
 SG_ Free_Station_Wagon_2_1 : 4|3@1+ (1,0) [0|0] "" XXX
 SG_ Followers_Recognized : 3|1@1+ (1,0) [0|0] "" XXX
 SG_ Error_Coolant_Temperature__4_1 : 2|1@1+ (1,0) [0|0] "" XXX
 SG_ Error_Status_Oil_Temperature_4_1 : 1|1@1+ (1,0) [0|0] "" XXX
 SG_ Error_Status_Outside_Temperature__4_1 : 0|1@1+ (1,0) [0|0] "" XXX

BO_ 800 Station_Wagon_1: 8 XXX
 SG_ Free_Station_Wagon_1_3 : 56|8@1+ (1,0) [0|0] "" XXX
 SG_ Displayed_Speed : 46|10@1+ (0.32,0) [0|325] "km/h" XXX
 SG_ Turn_Signal_Right_4_1 : 45|1@1+ (1,0) [0|0] "" XXX
 SG_ Turn_Signal_Left : 44|1@1+ (1,0) [0|0] "" XXX
 SG_ Set_Time_Gap__Station_Wagon_1_ : 43|1@1+ (1,0) [0|0] "" XXX
 SG_ ADR_Buzzer_Switched_Off : 42|1@1+ (1,0) [0|0] "" XXX
 SG_ Free_Station_Wagon_1_2 : 40|2@1+ (1,0) [0|0] "" XXX
 SG_ Speed__Station_Wagon_1 : 25|15@1+ (0.01,0) [0|326] "km/h" XXX
 SG_ Signal_Source_Speed_4_ : 24|1@1+ (1,0) [0|0] "" XXX
 SG_ Tank_Warning : 23|1@1+ (1,0) [0|0] "" XXX
 SG_ Tank_Capacity : 16|7@1+ (1,0) [0|126] "l" XXX
 SG_ Refueling_Stop : 15|1@1+ (1,0) [0|0] "" XXX
 SG_ Free_Station_Wagon_1_7 : 12|3@1+ (1,0) [0|0] "" XXX
 SG_ Station_Wagon_In_The_Actuator_Test : 11|1@1+ (1,0) [0|0] "" XXX
 SG_ Charging_Control_Lamp__Station_Wagon_ : 10|1@1+ (1,0) [0|0] "" XXX
 SG_ Brake_Info : 8|2@1+ (1,0) [0|0] "" XXX
 SG_ Glow_Lamp__Station_Wagon_1_ : 7|1@1+ (1,0) [0|0] "" XXX
 SG_ Fuel_Warning_Lamp : 6|1@1+ (1,0) [0|0] "" XXX
 SG_ Hot_Lights_Warning : 5|1@1+ (1,0) [0|0] "" XXX
 SG_ Coolant_Shortage : 4|1@1+ (1,0) [0|0] "" XXX
 SG_ Dynamic_Oil_Pressure_Warning : 3|1@1+ (1,0) [0|0] "" XXX
 SG_ Oil_Pressure : 2|1@1+ (1,0) [0|0] "" XXX
 SG_ Fault_Status_Tank : 1|1@1+ (1,0) [0|0] "" XXX
 SG_ Driver_Door_4_1 : 0|1@1+ (1,0) [0|0] "" XXX

BO_ 1504 Klima_1: 8 XXX
 SG_ Aussentemp__ungef__Sto_f__4_1 : 56|8@1+ (0.5,-50) [-50|77] "C" XXX
 SG_ Fehlerspeichereintrag__Klima_ : 55|1@1+ (1,0) [0|0] "" XXX
 SG_ Frei_Klima_1_5 : 50|5@1+ (1,0) [0|0] "" XXX
 SG_ AC_Schalter : 49|1@1+ (1,0) [0|0] "" XXX
 SG_ Temperatureinheit : 48|1@1+ (1,0) [0|0] "" XXX
 SG_ Kuehlerluefteransteuerung__Klim : 40|8@1+ (0.4,0) [0|101.6] "%" XXX
 SG_ Geblaeselast_4_1 : 32|8@1+ (0.4,0) [0|101.6] "%" XXX
 SG_ Kompressorlast : 24|8@1+ (0.25,0) [0|63.5] "Nm" XXX
 SG_ Klimadrucksignal__Klima_1_ : 16|8@1+ (0.2,0) [0|50.8] "bar" XXX
 SG_ Aussentemp__ungef__4_1__Klima_1 : 8|8@1+ (0.5,-50) [-50|77] "C" XXX
 SG_ Kaeltemitteldruck_veraltet : 7|1@1+ (1,0) [0|0] "" XXX
 SG_ Kompressormoment_veraltet_4_1 : 6|1@1+ (1,0) [0|0] "" XXX
 SG_ Keine_Heizleistg_gewuenscht_4_1 : 5|1@1+ (1,0) [0|0] "" XXX
 SG_ Kompressorzustand__4_1_ : 4|1@1+ (1,0) [0|0] "" XXX
 SG_ Heizbare_Frontscheibe : 3|1@1+ (1,0) [0|0] "" XXX
 SG_ Heizbare_Heckscheibe : 2|1@1+ (1,0) [0|0] "" XXX
 SG_ Fahrerwunsch_Zuheizer : 1|1@1+ (1,0) [0|0] "" XXX
 SG_ Drehzahlanhebung : 0|1@1+ (1,0) [0|0] "" XXX

BO_ 906 GRA_neu: 4 XXX
 SG_ Tiptronik_Bedienteilfehler : 31|1@1+ (1,0) [0|0] "" XXX
 SG_ Frei_GRA_neu_1_2 : 29|2@1+ (1,0) [0|0] "" XXX
 SG_ Limiter_ein : 28|1@1+ (1,0) [0|0] "" XXX
 SG_ Zeitlueckenverstellung : 26|2@1+ (1,0) [0|0] "" XXX
 SG_ Tiptronic_Tip_Up__4_1_ : 25|1@1+ (1,0) [0|0] "" XXX
 SG_ Tiptronic_Tip_Down__4_1_ : 24|1@1+ (1,0) [0|0] "" XXX
 SG_ Zaehler__GRA_neu_ : 20|4@1+ (1,0) [0|15] "" XXX
 SG_ Sender_Codierung__4_1_ : 18|2@1+ (1,0) [0|0] "" XXX
 SG_ Wiederaufnahme : 17|1@1+ (1,0) [0|0] "" XXX
 SG_ Setzen : 16|1@1+ (1,0) [0|0] "" XXX
 SG_ GRA_Neu_frei_1 : 15|1@1+ (1,0) [0|0] "" XXX
 SG_ Bedienteil_Fehler : 14|1@1+ (1,0) [0|0] "" XXX
 SG_ Lang_Tip_up : 13|1@1+ (1,0) [0|0] "" XXX
 SG_ Lang_Tip_down : 12|1@1+ (1,0) [0|0] "" XXX
 SG_ Kurz_Tip_up : 11|1@1+ (1,0) [0|0] "" XXX
 SG_ Kurz_Tip_down : 10|1@1+ (1,0) [0|0] "" XXX
 SG_ Abbrechen : 9|1@1+ (1,0) [0|0] "" XXX
 SG_ Checksumme_GRA_Neu : 0|8@1+ (1,0) [0|0] "" XXX
 SG_ Hauptschalter : 8|1@1+ (1,0) [0|0] "" XXX

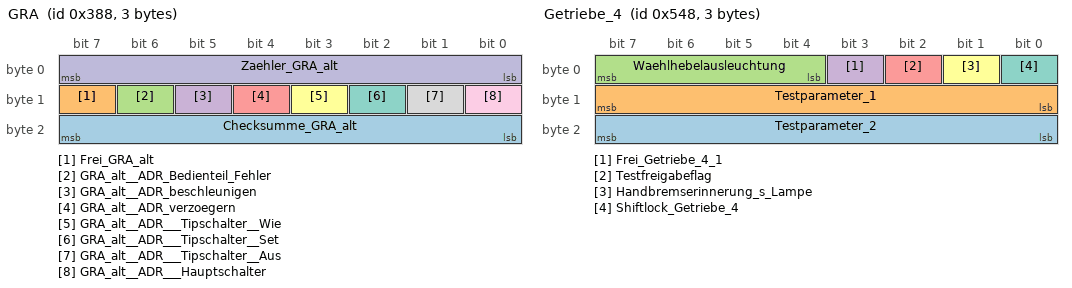
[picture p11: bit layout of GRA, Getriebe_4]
BO_ 904 GRA: 3 XXX
 SG_ Checksumme_GRA_alt : 16|8@1+ (1,0) [0|0] "" XXX
 SG_ Frei_GRA_alt : 15|1@1+ (1,0) [0|0] "" XXX
 SG_ GRA_alt__ADR_Bedienteil_Fehler : 14|1@1+ (1,0) [0|0] "" XXX
 SG_ GRA_alt__ADR_beschleunigen : 13|1@1+ (1,0) [0|0] "" XXX
 SG_ GRA_alt__ADR_verzoegern : 12|1@1+ (1,0) [0|0] "" XXX
 SG_ GRA_alt__ADR___Tipschalter__Wie : 11|1@1+ (1,0) [0|0] "" XXX
 SG_ GRA_alt__ADR___Tipschalter__Set : 10|1@1+ (1,0) [0|0] "" XXX
 SG_ GRA_alt__ADR___Tipschalter__Aus : 9|1@1+ (1,0) [0|0] "" XXX
 SG_ GRA_alt__ADR___Hauptschalter : 8|1@1+ (1,0) [0|0] "" XXX
 SG_ Zaehler_GRA_alt : 0|8@1+ (1,0) [0|255] "" XXX

BO_ 1352 Getriebe_4: 3 XXX
 SG_ Testparameter_2 : 16|8@1+ (1,0) [0|255] "" XXX
 SG_ Testparameter_1 : 8|8@1+ (1,0) [0|255] "" XXX
 SG_ Waehlhebelausleuchtung : 4|4@1+ (1,0) [0|0] "" XXX
 SG_ Frei_Getriebe_4_1 : 3|1@1+ (1,0) [0|0] "" XXX
 SG_ Testfreigabeflag : 2|1@1+ (1,0) [0|0] "" XXX
 SG_ Handbremserinnerung_s_Lampe : 1|1@1+ (1,0) [0|0] "" XXX
 SG_ Shiftlock_Getriebe_4 : 0|1@1+ (1,0) [0|0] "" XXX

BO_ 1344 Getriebe_2: 8 XXX
 SG_ eingelegte_Fahrstufe : 60|4@1+ (1,0) [0|0] "" XXX
 SG_ Ganganzeige_Kombi___Getriebe_Va : 56|4@1+ (1,0) [0|15] "" XXX
 SG_ Fehlerlampe_f_r_Kupplung_bei_VL : 55|1@1+ (1,0) [0|0] "" XXX
 SG_ Anforderung_Kriechadaption : 54|1@1+ (1,0) [0|0] "" XXX
 SG_ ECO_Anzeige__4_1_ : 53|1@1+ (1,0) [0|0] "" XXX
 SG_ Shift_Lock_Lampe : 52|1@1+ (1,0) [0|0] "" XXX
 SG_ Unterdrueckung_von_Warnungen : 51|1@1+ (1,0) [0|0] "" XXX
 SG_ Gong : 50|1@1+ (1,0) [0|0] "" XXX
 SG_ Starter_wird_angesteuert : 49|1@1+ (1,0) [0|0] "" XXX
 SG_ Hochschaltlampe : 48|1@1+ (1,0) [0|0] "" XXX
 SG_ Synchronisationszeit : 40|8@1+ (20,0) [0|5080] "ms" XXX
 SG_ invertierte_Synchronisations_Wu : 32|8@1+ (25,0) [0|6350] "U/min" XXX
 SG_ Synchronisations_Wunschdrehzahl : 24|8@1+ (25,0) [0|6350] "U/min" XXX
 SG_ Gradientenbegrenzung : 16|8@1+ (10,0) [0|2540] "Nm/s" XXX
 SG_ Leerlaufsolldrehzahl__Getriebe : 8|8@1+ (10,0) [0|2540] "U/min" XXX
 SG_ Zahler_Getriebe_2 : 4|4@1+ (1,0) [0|15] "" XXX
 SG_ Zwischengasflag : 3|1@1+ (1,0) [0|0] "" XXX
 SG_ Ecomatic__4_1_ : 2|1@1+ (1,0) [0|0] "" XXX
 SG_ Schubabschaltunterstuetzung : 1|1@1+ (1,0) [0|0] "" XXX
 SG_ LFR_Adaption_Freigabeflag : 0|1@1+ (1,0) [0|0] "" XXX

BO_ 1088 Getriebe_1: 8 XXX
 SG_ Wandlerverlustmoment : 56|8@1+ (0.39,0) [0|99.06] "MDI" XXX
 SG_ Fehlerspeichereintrag__Getriebe : 55|1@1+ (1,0) [0|0] "" XXX
 SG_ Zaehler_Getriebe_1 : 51|4@1+ (1,0) [0|15] "" XXX
 SG_ Gang_eingelegt : 50|1@1+ (1,0) [0|0] "" XXX
 SG_ Schaltabsicht : 49|1@1+ (1,0) [0|0] "" XXX
 SG_ Motor_aus : 48|1@1+ (1,0) [0|0] "" XXX
 SG_ OBD_Status__Getriebe_1___4_1_ : 46|2@1+ (1,0) [0|0] "" XXX
 SG_ Kuehlleistung : 44|2@1+ (1,0) [0|0] "" XXX
 SG_ Getriebe_Notlauf : 40|4@1+ (1,0) [0|0] "" XXX
 SG_ Fahrwiderstandsindex : 32|8@1+ (0.249,-31.6) [-31.6|31.6] "" XXX
 SG_ inneres_Soll_Motormoment : 24|8@1+ (0.39,0) [0|99.06] "MDI" XXX
 SG_ Uebertragungsfunktion : 16|8@1+ (0.1,0) [0|25.4] "" XXX
 SG_ Waehlhebelposition__Getriebe_1_ : 12|4@1+ (1,0) [0|0] "" XXX
 SG_ Zielgang_oder_eingelegter_Gang : 8|4@1+ (1,0) [0|0] "" XXX
 SG_ EGS_Anforderung : 7|1@1+ (1,0) [0|0] "" XXX
 SG_ Kodierung_im_MSG : 6|1@1+ (1,0) [0|0] "" XXX
 SG_ Leerlaufsolldrehzahlanhebung : 5|1@1+ (1,0) [0|0] "" XXX
 SG_ Wandlerkupplung : 3|2@1+ (1,0) [0|0] "" XXX
 SG_ Klimakompressor_aus__Getriebe_1 : 2|1@1+ (1,0) [0|0] "" XXX
 SG_ Status_Getriebe_und_Wandlerschu : 1|1@1+ (1,0) [0|0] "" XXX
 SG_ Schaltung_aktiv__Getriebe_1_ : 0|1@1+ (1,0) [0|0] "" XXX

BO_ 912 Gateway_Komfort_1: 6 XXX
 SG_ Bremslicht_Anhaenger : 47|1@1+ (1,0) [0|0] "" XXX
 SG_ Anhaenger_erkannt_Gateway : 46|1@1+ (1,0) [0|0] "" XXX
 SG_ ECD_AAG_unplausibel : 45|1@1+ (1,0) [0|0] "" XXX
 SG_ BLS_AAG_unplausibel : 44|1@1+ (1,0) [0|0] "" XXX
 SG_ ECD_ILM_unplausibel : 33|1@1+ (1,0) [0|0] "" XXX
 SG_ BLS_ILM_unplausibel : 32|1@1+ (1,0) [0|0] "" XXX
 SG_ Bremslicht_mitte_defekt : 31|1@1+ (1,0) [0|0] "" XXX
 SG_ Bremslicht_rechts_defekt : 30|1@1+ (1,0) [0|0] "" XXX
 SG_ Bremslicht_links_defekt : 29|1@1+ (1,0) [0|0] "" XXX
 SG_ Rueckfahrlicht_Gateway : 28|1@1+ (1,0) [0|0] "" XXX
 SG_ Zaehler_Bremslicht : 24|4@1+ (1,0) [0|15] "" XXX
 SG_ Frei_Gateway_Komfort_1_3 : 17|7@1+ (1,0) [0|0] "" XXX
 SG_ RDK_Systemfehler : 15|1@1+ (1,0) [0|0] "" XXX
 SG_ RDK_Warnstufe_1 : 14|1@1+ (1,0) [0|0] "" XXX
 SG_ RDK_Warnstufe_2 : 13|1@1+ (1,0) [0|0] "" XXX
 SG_ Reifendruckwarnung_Reserverad : 12|1@1+ (1,0) [0|0] "" XXX
 SG_ Reifendruckwarnung_hinten_recht : 11|1@1+ (1,0) [0|0] "" XXX
 SG_ Reifendruckwarnung_hinten_links : 10|1@1+ (1,0) [0|0] "" XXX
 SG_ Reifendruckwarnung_vorn_rechts : 9|1@1+ (1,0) [0|0] "" XXX
 SG_ Reifendruckwarnung_vorn_links : 8|1@1+ (1,0) [0|0] "" XXX
 SG_ Frei_Gateway_Komfort_1_2 : 5|3@1+ (1,0) [0|0] "" XXX
 SG_ Fahrertuerkontakt_veraltet : 4|1@1+ (1,0) [0|0] "" XXX
 SG_ Frei_Gateway_Komfort_1_1 : 3|1@1+ (1,0) [0|0] "" XXX
 SG_ Licht_1_Botschaft_veraltet : 2|1@1+ (1,0) [0|0] "" XXX
 SG_ Anhaenger_Botschaft_veraltet : 1|1@1+ (1,0) [0|0] "" XXX
 SG_ Reifendruckwarnung_veraltet : 0|1@1+ (1,0) [0|0] "" XXX
 SG_ Fahrertuerkontakt : 16|1@1+ (1,0) [0|0] "" XXX
 SG_ Zaehler_Anhaenger : 40|4@1+ (1,0) [0|15] "" XXX
 SG_ Frei_Gateway_Komfort_1_4 : 34|6@1+ (1,0) [0|0] "" XXX

BO_ 1340 Fahrwerk_1: 1 XXX
 SG_ Frei_Fahrwerk_1_2 : 7|1@1+ (1,0) [0|0] "" XXX
 SG_ Frei_Fahrwerk_1_1 : 6|2@1+ (1,0) [0|0] "" XXX
 SG_ Einstellung_Fahrwerkdaempfung_4 : 4|3@1+ (1,0) [0|7] "" XXX
 SG_ Ansteuererung_Fahrzeugniveau : 0|4@1+ (1,0) [0|15] "" XXX

BO_ 1472 EPB_1: 8 XXX
 SG_ Textmeldungen_EPB : 52|4@1+ (1,0) [0|0] "" XXX
 SG_ Aufmerksamkeits_Gtong_EPB : 51|1@1+ (1,0) [0|0] "" XXX
 SG_ Fehler_Gong_EBP : 50|1@1+ (1,0) [0|0] "" XXX
 SG_ Warnton_EPB : 49|1@1+ (1,0) [0|0] "" XXX
 SG_ Funktionslampe_EPB : 48|1@1+ (1,0) [0|0] "" XXX
 SG_ Frei_EPB_1_1 : 33|15@1+ (1,0) [0|0] "" XXX
 SG_ Fehlerspeichereintrag_EPB : 32|1@1+ (1,0) [0|0] "" XXX
 SG_ Neigungswinkel : 24|8@1+ (1,-128) [-128|127] "g" XXX
 SG_ Verzoegerungsanforderung__EPB_ : 24|8@1+ (0.5,0) [0|255] "g" XXX
 SG_ Status_Neigungswinkelgeber : 15|1@1+ (1,0) [0|0] "" XXX
 SG_ Schalterinfo_Parkbremse : 13|2@1+ (1,0) [0|0] "" XXX
 SG_ Erreichte_Spannkraft : 8|5@1+ (1,0) [0|30] "kN" XXX
 SG_ Checksumme_Parkbremse : 8|8@1+ (1,0) [0|255] "" XXX
 SG_ Schalterstatus_Parkbremse : 7|1@1+ (1,0) [0|0] "" XXX
 SG_ Status_Parkbremse : 6|1@1+ (1,0) [0|0] "" XXX
 SG_ Fehlerstatus_Parkbremse : 4|2@1+ (1,0) [0|0] "" XXX
 SG_ Zaehler_Parkbremse : 0|4@1+ (1,0) [0|0] "" XXX

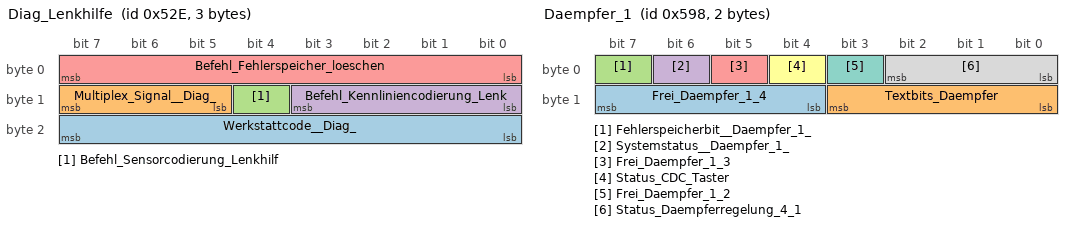
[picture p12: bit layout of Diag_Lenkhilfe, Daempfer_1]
BO_ 1326 Diag_Lenkhilfe: 3 XXX
 SG_ Werkstattcode__Diag_ : 16|8@1+ (1,0) [0|0] "" XXX
 SG_ Multiplex_Signal__Diag_ : 13|3@1+ (1,0) [0|7] "" XXX
 SG_ Befehl_Sensorcodierung_Lenkhilf : 12|1@1+ (1,0) [0|0] "" XXX
 SG_ Befehl_Kennliniencodierung_Lenk : 8|4@1+ (1,0) [0|0] "" XXX
 SG_ Befehl_Fehlerspeicher_loeschen : 0|8@1+ (1,0) [0|0] "" XXX

BO_ 1432 Daempfer_1: 2 XXX
 SG_ Frei_Daempfer_1_4 : 12|4@1+ (1,0) [0|0] "" XXX
 SG_ Textbits_Daempfer : 8|4@1+ (1,0) [0|0] "" XXX
 SG_ Fehlerspeicherbit__Daempfer_1_ : 7|1@1+ (1,0) [0|0] "" XXX
 SG_ Systemstatus__Daempfer_1_ : 6|1@1+ (1,0) [0|0] "" XXX
 SG_ Frei_Daempfer_1_3 : 5|1@1+ (1,0) [0|0] "" XXX
 SG_ Status_CDC_Taster : 4|1@1+ (1,0) [0|0] "" XXX
 SG_ Frei_Daempfer_1_2 : 3|1@1+ (1,0) [0|0] "" XXX
 SG_ Status_Daempferregelung_4_1 : 0|3@1+ (1,0) [0|7] "" XXX

BO_ 1392 BSG_Last: 4 XXX
 SG_ Klimaanlage_abschalten : 31|1@1+ (1,0) [0|0] "" XXX
 SG_ Sitzbelueftung_abschalten : 30|1@1+ (1,0) [0|0] "" XXX
 SG_ Wischwasserheizung_abschalten : 29|1@1+ (1,0) [0|0] "" XXX
 SG_ Lenkradheizung_abschalten : 28|1@1+ (1,0) [0|0] "" XXX
 SG_ Heizbare_Sitze_abschalten : 27|1@1+ (1,0) [0|0] "" XXX
 SG_ Heizbare_Aussenspiegel_abschalt : 26|1@1+ (1,0) [0|0] "" XXX
 SG_ Heizbare_Frontscheibe_abschalte : 25|1@1+ (1,0) [0|0] "" XXX
 SG_ Heizbare_Heckscheibe_abschalten : 24|1@1+ (1,0) [0|0] "" XXX
 SG_ Batteriespannung_Bordnetzbatter : 16|8@1+ (0.05,5) [5|17.7] "V" XXX
 SG_ Motorhaubenkontakt : 15|1@1+ (1,0) [0|0] "" XXX
 SG_ Leuchtweitenregulierung : 14|1@1+ (1,0) [0|0] "" XXX
 SG_ Fehlerspeichereintrag__BSG_Last : 13|1@1+ (1,0) [0|0] "" XXX
 SG_ Zustand_der_Starterbatterie : 11|2@1+ (1,0) [0|0] "" XXX
 SG_ Zustand_der_Bordnetzbatterie : 9|2@1+ (1,0) [0|0] "" XXX
 SG_ LL_Drehzahlanhebung : 8|1@1+ (1,0) [0|0] "" XXX
 SG_ Klemme_L : 7|1@1+ (1,0) [0|0] "" XXX
 SG_ Frei_BSG_Last_1_1 : 4|3@1+ (1,0) [0|0] "" XXX
 SG_ ZAS_Klemme_50 : 3|1@1+ (1,0) [0|0] "" XXX
 SG_ ZAS_Klemme_X : 2|1@1+ (1,0) [0|0] "" XXX
 SG_ ZAS_Klemme_15 : 1|1@1+ (1,0) [0|0] "" XXX
 SG_ ZAS_Klemme_S : 0|1@1+ (1,0) [0|0] "" XXX

BO_ 1136 BSG_Kombi: 5 XXX
 SG_ Frei_BSG_Kombi_1_3 : 36|4@1+ (1,0) [0|0] "" XXX
 SG_ Ruecksitzlehne_HR_verr__4_1 : 35|1@1+ (1,0) [0|0] "" XXX
 SG_ Ruecksitzlehne_HL_verr__4_1 : 34|1@1+ (1,0) [0|0] "" XXX
 SG_ Fehlerlampe_Lenkhilfe_veraltet : 33|1@1+ (1,0) [0|0] "" XXX
 SG_ Fehlerlampe_Lenkhilfe__BSG_Komb : 32|1@1+ (1,0) [0|0] "" XXX
 SG_ Fehlerstatus_Kl__58s : 31|1@1+ (1,0) [0|0] "" XXX
 SG_ Klemme_58s__BSG_Kombi_ : 24|7@1+ (1,0) [0|100] "%" XXX
 SG_ Fehlerstatus_Kl__58d : 23|1@1+ (1,0) [0|0] "" XXX
 SG_ Klemme_58d__BSG_Kombi_ : 16|7@1+ (1,0) [0|100] "%" XXX
 SG_ Unterspannung : 15|1@1+ (1,0) [0|0] "" XXX
 SG_ Frei_BSG_Kombi_1_2 : 14|1@1+ (1,0) [0|0] "" XXX
 SG_ Heckdeckel_geoeffnet : 13|1@1+ (1,0) [0|0] "" XXX
 SG_ Motorhaube_geoeffnet : 12|1@1+ (1,0) [0|0] "" XXX
 SG_ Tuer_hinten_rechts_geoeffnet : 11|1@1+ (1,0) [0|0] "" XXX
 SG_ Tuer_hinten_links_geoeffnet : 10|1@1+ (1,0) [0|0] "" XXX
 SG_ Beifahrertuer_geoeffnet : 9|1@1+ (1,0) [0|0] "" XXX
 SG_ Fahrertuer_geoeffnet : 8|1@1+ (1,0) [0|0] "" XXX
 SG_ Lade_Kontrollampe : 7|1@1+ (1,0) [0|0] "" XXX
 SG_ Frei_BSG_Kombi_1_1 : 6|1@1+ (1,0) [0|0] "" XXX
 SG_ Rueckfahrlicht : 5|1@1+ (1,0) [0|0] "" XXX
 SG_ DWA_Akku : 4|1@1+ (1,0) [0|0] "" XXX
 SG_ Warnblink_Mode : 3|1@1+ (1,0) [0|0] "" XXX
 SG_ Anhaenger_Kontrollampe : 2|1@1+ (1,0) [0|0] "" XXX
 SG_ Blinker_rechts_Kontrollampe : 1|1@1+ (1,0) [0|0] "" XXX
 SG_ Blinker_links_Kontrollampe : 0|1@1+ (1,0) [0|0] "" XXX

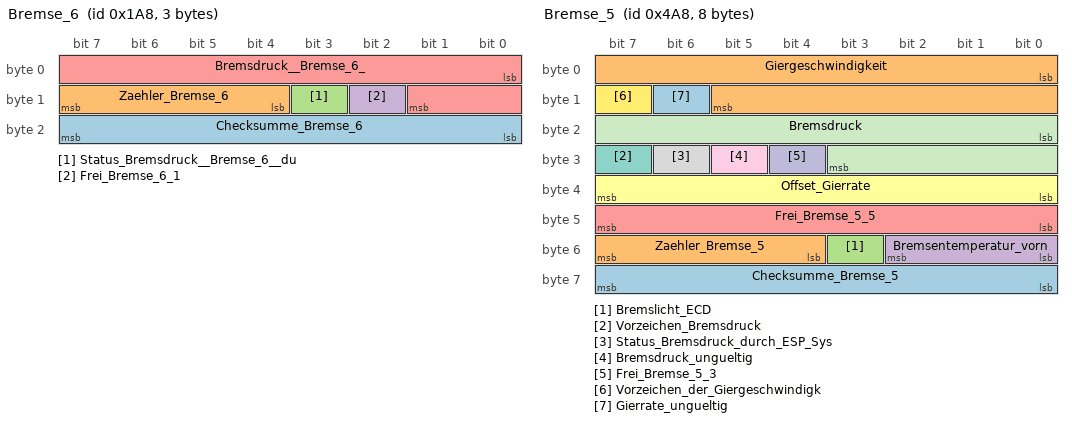
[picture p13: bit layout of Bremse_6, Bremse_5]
BO_ 424 Bremse_6: 3 XXX
 SG_ Checksumme_Bremse_6 : 16|8@1+ (1,0) [0|0] "" XXX
 SG_ Zaehler_Bremse_6 : 12|4@1+ (1,0) [0|15] "" XXX
 SG_ Status_Bremsdruck__Bremse_6__du : 11|1@1+ (1,0) [0|0] "" XXX
 SG_ Frei_Bremse_6_1 : 10|1@1+ (1,0) [0|0] "" XXX
 SG_ Bremsdruck__Bremse_6_ : 0|10@1+ (0.3255,-40) [-40|293] "bar" XXX

BO_ 1192 Bremse_5: 8 XXX
 SG_ Checksumme_Bremse_5 : 56|8@1+ (1,0) [0|0] "" XXX
 SG_ Zaehler_Bremse_5 : 52|4@1+ (1,0) [0|15] "" XXX
 SG_ Bremslicht_ECD : 51|1@1+ (1,0) [0|0] "" XXX
 SG_ Bremsentemperatur_vorn : 48|3@1+ (125,125) [125|1000] "C" XXX
 SG_ Frei_Bremse_5_5 : 40|8@1+ (1,0) [0|0] "" XXX
 SG_ Offset_Gierrate : 32|8@1+ (0.05,-6.375) [-6.375|6.375] "deg/s" XXX
 SG_ Vorzeichen_Bremsdruck : 31|1@1+ (1,0) [0|0] "" XXX
 SG_ Status_Bremsdruck_durch_ESP_Sys : 30|1@1+ (1,0) [0|0] "" XXX
 SG_ Bremsdruck_ungueltig : 29|1@1+ (1,0) [0|0] "" XXX
 SG_ Frei_Bremse_5_3 : 28|1@1+ (1,0) [0|0] "" XXX
 SG_ Bremsdruck : 16|12@1+ (0.1,0) [0|250] "bar" XXX
 SG_ Vorzeichen_der_Giergeschwindigk : 15|1@1+ (1,0) [0|0] "" XXX
 SG_ Gierrate_ungueltig : 14|1@1+ (1,0) [0|0] "" XXX
 SG_ Giergeschwindigkeit : 0|14@1+ (0.01,0) [0|100] "Grad/sec" XXX

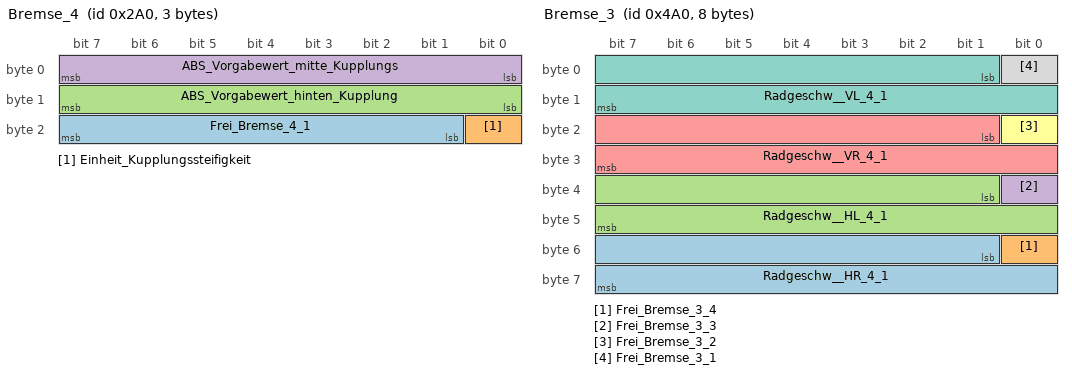
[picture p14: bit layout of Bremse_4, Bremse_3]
BO_ 672 Bremse_4: 3 XXX
 SG_ Frei_Bremse_4_1 : 17|7@1+ (1,0) [0|0] "" XXX
 SG_ Einheit_Kupplungssteifigkeit : 16|1@1+ (1,0) [0|0] "" XXX
 SG_ ABS_Vorgabewert_hinten_Kupplung : 8|8@1+ (0.7874,0) [0|100] "%" XXX
 SG_ ABS_Vorgabewert_mitte_Kupplungs : 0|8@1+ (3,-381) [-381|378] "Nm/min" XXX

BO_ 1184 Bremse_3: 8 XXX
 SG_ Radgeschw__HR_4_1 : 49|15@1+ (0.01,0) [0|326] "km/h" XXX
 SG_ Frei_Bremse_3_4 : 48|1@1+ (1,0) [0|0] "" XXX
 SG_ Radgeschw__HL_4_1 : 33|15@1+ (0.01,0) [0|326] "km/h" XXX
 SG_ Frei_Bremse_3_3 : 32|1@1+ (1,0) [0|0] "" XXX
 SG_ Radgeschw__VR_4_1 : 17|15@1+ (0.01,0) [0|326] "km/h" XXX
 SG_ Frei_Bremse_3_2 : 16|1@1+ (0.01,0) [0|325] "km/h" XXX
 SG_ Radgeschw__VL_4_1 : 1|15@1+ (0.01,0) [0|326] "km/h" XXX
 SG_ Frei_Bremse_3_1 : 0|1@1+ (1,0) [0|0] "" XXX

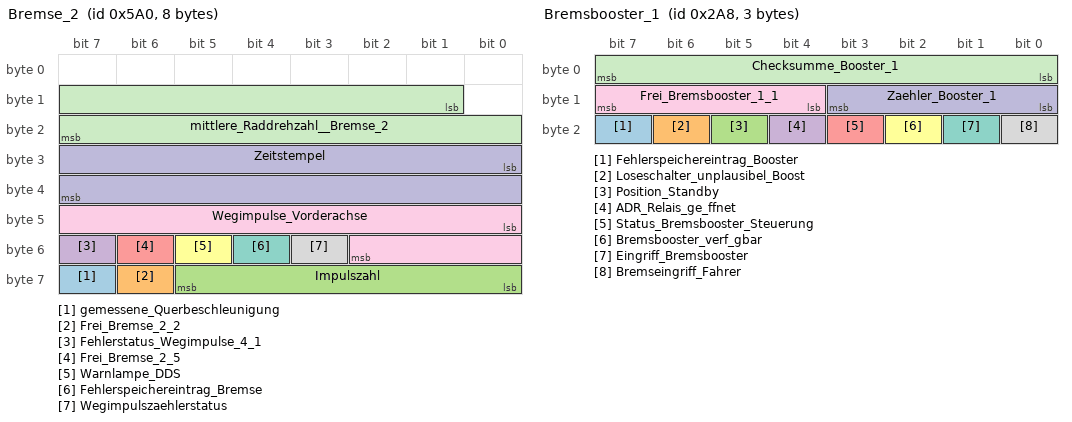
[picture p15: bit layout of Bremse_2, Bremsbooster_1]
BO_ 1440 Bremse_2: 8 XXX
 SG_ gemessene_Querbeschleunigung : 63|1@1+ (1,0) [0|0] "" XXX
 SG_ Frei_Bremse_2_2 : 62|1@1+ (1,0) [0|0] "" XXX
 SG_ Impulszahl : 56|6@1+ (1,0) [0|63] "" XXX
 SG_ Fehlerstatus_Wegimpulse_4_1 : 55|1@1+ (1,0) [0|0] "" XXX
 SG_ Frei_Bremse_2_5 : 54|1@1+ (1,0) [0|0] "" XXX
 SG_ Warnlampe_DDS : 53|1@1+ (1,0) [0|0] "" XXX
 SG_ Fehlerspeichereintrag_Bremse : 52|1@1+ (1,0) [0|0] "" XXX
 SG_ Wegimpulszaehlerstatus : 51|1@1+ (1,0) [0|0] "" XXX
 SG_ Wegimpulse_Vorderachse : 40|11@1+ (1,0) [0|2047] "" XXX
 SG_ Zeitstempel : 24|16@1+ (1,0) [0|65535] "tics" XXX
 SG_ mittlere_Raddrehzahl__Bremse_2 : 9|15@1+ (0.002,0) [0|65.278] "U/sec" XXX

BO_ 416 Bremse_1: 8 XXX
 SG_ Geschwindigkeitsersatzwert : 63|1@1+ (1,0) [0|0] "" XXX
 SG_ ESP_Systemstatus_4_1 : 62|1@1+ (1,0) [0|0] "" XXX
 SG_ ESP_Passiv_getastet : 61|1@1+ (1,0) [0|0] "" XXX
 SG_ ASR_Steuerger_t : 60|1@1+ (1,0) [0|0] "" XXX
 SG_ Zaehler_Bremse_1 : 56|4@1+ (1,0) [0|15] "" XXX
 SG_ MSR_Eingriffsmoment : 48|8@1+ (0.39,0) [0|99.06] "MDI" XXX
 SG_ ASR_Eingriffsmoment_schnell : 40|8@1+ (0.39,0) [0|99.06] "MDI" XXX
 SG_ ASR_Eingriffsmoment_langsam : 32|8@1+ (0.39,0) [0|99.06] "MDI" XXX
 SG_ Geschwindigkeit_neu__Bremse_1_ : 17|15@1+ (0.01,0) [0|326.39] "km/h" XXX
 SG_ Aktiver_Bremskraftverstaerker : 16|1@1+ (1,0) [0|0] "" XXX
 SG_ ABS_in_Diagnose : 15|1@1+ (1,0) [0|0] "" XXX
 SG_ Fehlerstatus_Schlechtwegausblen : 14|1@1+ (1,0) [0|0] "" XXX
 SG_ Schlechtwegausblendung : 13|1@1+ (1,0) [0|0] "" XXX
 SG_ Fahrer_bremst__Bremse_1___4_1_ : 11|1@1+ (1,0) [0|0] "" XXX
 SG_ Bremskontroll_Lampe : 10|1@1+ (1,0) [0|0] "" XXX
 SG_ Lampe_ASR___ESP : 9|1@1+ (1,0) [0|0] "" XXX
 SG_ Lampe_ABS : 8|1@1+ (1,0) [0|0] "" XXX
 SG_ EBV_Eingriff : 7|1@1+ (1,0) [0|0] "" XXX
 SG_ ASR_Schaltbeeinflussung : 5|2@1+ (1,0) [0|0] "" XXX
 SG_ ESP_Eingriff : 4|1@1+ (1,0) [0|0] "" XXX
 SG_ EDS_Eingriff : 3|1@1+ (1,0) [0|0] "" XXX
 SG_ ABS_Bremsung__4_1_ : 2|1@1+ (1,0) [0|0] "" XXX
 SG_ MSR_Anforderung : 1|1@1+ (1,0) [0|0] "" XXX
 SG_ ASR_Anforderung : 0|1@1+ (1,0) [0|0] "" XXX

BO_ 680 Bremsbooster_1: 3 XXX
 SG_ Fehlerspeichereintrag_Booster : 23|1@1+ (1,0) [0|0] "" XXX
 SG_ Loseschalter_unplausibel_Boost : 22|1@1+ (1,0) [0|0] "" XXX
 SG_ Position_Standby : 21|1@1+ (1,0) [0|0] "" XXX
 SG_ ADR_Relais_ge_ffnet : 20|1@1+ (1,0) [0|0] "" XXX
 SG_ Status_Bremsbooster_Steuerung : 19|1@1+ (1,0) [0|0] "" XXX
 SG_ Bremsbooster_verf_gbar : 18|1@1+ (1,0) [0|0] "" XXX
 SG_ Eingriff_Bremsbooster : 17|1@1+ (1,0) [0|0] "" XXX
 SG_ Bremseingriff_Fahrer : 16|1@1+ (1,0) [0|0] "" XXX
 SG_ Frei_Bremsbooster_1_1 : 12|4@1+ (1,0) [0|0] "" XXX
 SG_ Zaehler_Booster_1 : 8|4@1+ (1,0) [0|15] "" XXX
 SG_ Checksumme_Booster_1 : 0|8@1+ (1,0) [0|0] "" XXX

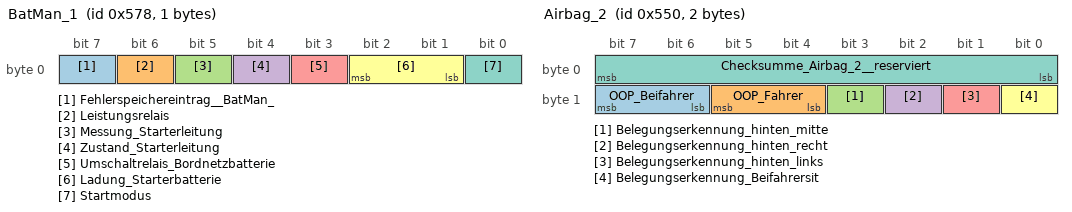
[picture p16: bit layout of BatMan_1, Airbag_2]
BO_ 1400 BatMan_1: 1 XXX
 SG_ Fehlerspeichereintrag__BatMan_ : 7|1@1+ (1,0) [0|0] "" XXX
 SG_ Leistungsrelais : 6|1@1+ (1,0) [0|0] "" XXX
 SG_ Messung_Starterleitung : 5|1@1+ (1,0) [0|0] "" XXX
 SG_ Zustand_Starterleitung : 4|1@1+ (1,0) [0|0] "" XXX
 SG_ Umschaltrelais_Bordnetzbatterie : 3|1@1+ (1,0) [0|0] "" XXX
 SG_ Ladung_Starterbatterie : 1|2@1+ (1,0) [0|0] "" XXX
 SG_ Startmodus : 0|1@1+ (1,0) [0|0] "" XXX

BO_ 704 Allrad_1: 5 XXX
 SG_ Kupplungssteifigkeit_Hinten__Is : 32|8@1+ (0.7874,0) [0|100] "%" XXX
 SG_ Fehlerspeichereintrag_Allrad_1 : 31|1@1+ (1,0) [0|0] "" XXX
 SG_ Frei_Allrad_1_1 : 26|5@1+ (1,0) [0|0] "" XXX
 SG_ Schaltung_Vorwarnung : 25|1@1+ (1,0) [0|0] "" XXX
 SG_ Schaltung_aktiv__Allrad_1_ : 24|1@1+ (1,0) [0|0] "" XXX
 SG_ Ganginfo__PNG_ : 20|4@1+ (1,0) [0|0] "" XXX
 SG_ PNG_Anzeige_blinkend : 19|1@1+ (1,0) [0|0] "" XXX
 SG_ PNG_Status_4_1 : 16|3@1+ (1,0) [0|0] "" XXX
 SG_ Kupplungssteifigkeit_Mitte__Ist : 8|8@1+ (3,-381) [-381|378] "Nm/min" XXX
 SG_ Einheit_der_Kupplungssteifigkei : 7|1@1+ (1,0) [0|0] "" XXX
 SG_ Geschwindigkeitsbegrenzung : 6|1@1+ (1,0) [0|0] "" XXX
 SG_ Allrad_Warnlampe : 5|1@1+ (1,0) [0|0] "" XXX
 SG_ Notlauf : 4|1@1+ (1,0) [0|0] "" XXX
 SG_ Kupplung_komplett_offen : 3|1@1+ (1,0) [0|0] "" XXX
 SG_ Fehlerstatus_Kupplungssteifigke : 2|1@1+ (1,0) [0|0] "" XXX
 SG_ Ubertemperaturschutz__Allrad_1_ : 1|1@1+ (1,0) [0|0] "" XXX
 SG_ Fehler_Allrad_Kupplung : 0|1@1+ (1,0) [0|0] "" XXX

BO_ 1360 Airbag_2: 2 XXX
 SG_ OOP_Beifahrer : 14|2@1+ (1,0) [0|0] "" XXX
 SG_ OOP_Fahrer : 12|2@1+ (1,0) [0|0] "" XXX
 SG_ Belegungserkennung_hinten_mitte : 11|1@1+ (1,0) [0|0] "" XXX
 SG_ Belegungserkennung_hinten_recht : 10|1@1+ (1,0) [0|0] "" XXX
 SG_ Belegungserkennung_hinten_links : 9|1@1+ (1,0) [0|0] "" XXX
 SG_ Belegungserkennung_Beifahrersit : 8|1@1+ (1,0) [0|0] "" XXX
 SG_ Checksumme_Airbag_2__reserviert : 0|8@1+ (1,0) [0|0] "" XXX

BO_ 80 Airbag_1: 4 XXX
 SG_ Checksumme_Airbag_1 : 24|8@1+ (1,0) [0|0] "" XXX
 SG_ Zaehler_Airbag_1 : 20|4@1+ (1,0) [0|15] "" XXX
 SG_ Fehlerspeichereintrag : 19|1@1+ (1,0) [0|0] "" XXX
 SG_ Frei_Airbag_1_2 : 18|1@1+ (1,0) [0|0] "" XXX
 SG_ Airbag_im_Stellgliedtest : 17|1@1+ (1,0) [0|0] "" XXX
 SG_ Airbag_in_Diagnose : 16|1@1+ (1,0) [0|0] "" XXX
 SG_ Gurtwarnung_Beifahrer : 15|1@1+ (1,0) [0|0] "" XXX
 SG_ Gurtschalter_Beifahrer : 14|1@1+ (1,0) [0|0] "" XXX
 SG_ Gurtwarnung_Fahrer : 13|1@1+ (1,0) [0|0] "" XXX
 SG_ Airbag_Systemfehler : 11|1@1+ (1,0) [0|0] "" XXX
 SG_ Kindersitzerkennung : 10|1@1+ (1,0) [0|0] "" XXX
 SG_ Airbag_deaktiviert : 9|1@1+ (1,0) [0|0] "" XXX
 SG_ Airbag_Lampe : 8|1@1+ (1,0) [0|0] "" XXX
 SG_ Crash_Intensitaet : 5|3@1+ (1,0) [0|111] "B" XXX
 SG_ Rollover : 4|1@1+ (1,0) [0|0] "" XXX
 SG_ Seiten_Crash_Beifahrer : 3|1@1+ (1,0) [0|0] "" XXX
 SG_ Seiten_Crash_Fahrer : 2|1@1+ (1,0) [0|0] "" XXX
 SG_ Heck_Crash : 1|1@1+ (1,0) [0|0] "" XXX
 SG_ Front_Crash : 0|1@1+ (1,0) [0|0] "" XXX
 SG_ Gurtschalter_Fahrer : 12|1@1+ (1,0) [0|0] "" XXX

BO_ 864 ADR_System: 8 XXX
 SG_ S_Checksumme_ADR_1 : 56|8@1+ (1,0) [0|0] "" XXX
 SG_ S_Frei_ADR_1_1 : 52|4@1+ (1,0) [0|0] "" XXX
 SG_ S_Zeitluecke_gemessen : 48|4@1+ (1,0) [0|15] "" XXX
 SG_ S_Fehlerspeichereintrag_ADR : 47|1@1+ (1,0) [0|0] "" XXX
 SG_ S_Fehlerspeichereintrag_Bremsbo : 46|1@1+ (1,0) [0|0] "" XXX
 SG_ S_ADR_Relais_geoeffnet : 45|1@1+ (1,0) [0|0] "" XXX
 SG_ S_Bremsbooster_Status : 43|2@1+ (1,0) [0|0] "" XXX
 SG_ S_Eingriff_Bremsbooster : 42|1@1+ (1,0) [0|0] "" XXX
 SG_ S_Loeseschalter_unplausibel : 41|1@1+ (1,0) [0|0] "" XXX
 SG_ S_Bremseingriff_Fahrer : 40|1@1+ (1,0) [0|0] "" XXX
 SG_ S_Anzeige_Sensor_blind : 39|1@1+ (1,0) [0|0] "" XXX
 SG_ S_Ansteuerung_optischer_Fahrerh : 38|1@1+ (1,0) [0|0] "" XXX
 SG_ S_Ansteuerung_Gong_2 : 37|1@1+ (1,0) [0|0] "" XXX
 SG_ S_Ansteuerung_Gong_1 : 36|1@1+ (1,0) [0|0] "" XXX
 SG_ S_Schaltaufforderung : 34|2@1+ (1,0) [0|0] "" XXX
 SG_ S_Anzeige_Prioritaet : 33|1@1+ (1,0) [0|0] "" XXX
 SG_ S_Anzeige_Zeitluecke : 32|1@1+ (1,0) [0|0] "" XXX
 SG_ S_Wunschgeschwindigkeit : 24|8@1+ (1,0) [0|254] "km/h" XXX
 SG_ S_Objekt_erfasst : 22|2@1+ (1,0) [0|0] "" XXX
 SG_ S_Gesetzte_Zeitluecke__ADR_1_ : 18|4@1+ (1,0) [0|15] "" XXX
 SG_ S_Synchronisation_Bremsbooster : 17|1@1+ (1,0) [0|0] "" XXX
 SG_ S_Momentenanforderung_Freigabe : 16|1@1+ (1,0) [0|0] "" XXX
 SG_ S_Verhinderung_Schubabschaltung : 15|1@1+ (1,0) [0|0] "" XXX
 SG_ S_Status_ADR_1__S_ : 13|2@1+ (1,0) [0|0] "" XXX
 SG_ S_Fehler_ADR_1__S_ : 12|1@1+ (1,0) [0|0] "" XXX
 SG_ S_Zaehler_ADR_1 : 8|4@1+ (1,0) [0|15] "" XXX
 SG_ S_Momentenanforderung_ADR : 0|8@1+ (0.39,0) [0|99] "MDI" XXX

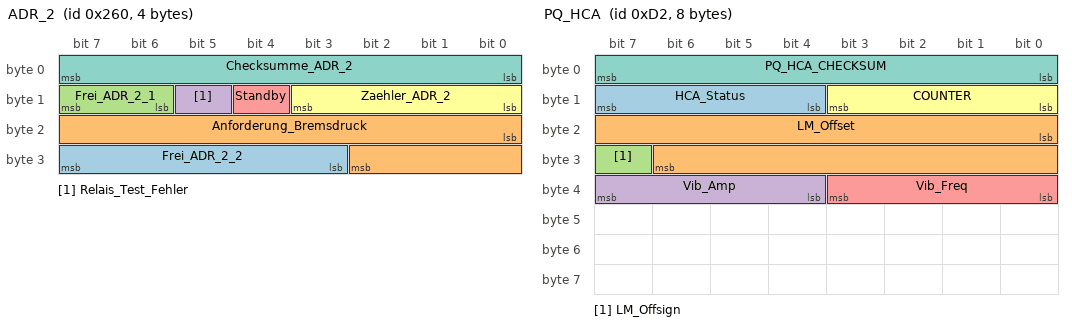
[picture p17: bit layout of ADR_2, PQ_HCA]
BO_ 608 ADR_2: 4 XXX
 SG_ Frei_ADR_2_2 : 27|5@1+ (1,0) [0|0] "" XXX
 SG_ Anforderung_Bremsdruck : 16|11@1+ (0.0625,0) [0|127.9375] "bar" XXX
 SG_ Frei_ADR_2_1 : 14|2@1+ (1,0) [0|0] "" XXX
 SG_ Relais_Test_Fehler : 13|1@1+ (1,0) [0|0] "" XXX
 SG_ Standby : 12|1@1+ (1,0) [0|0] "" XXX
 SG_ Zaehler_ADR_2 : 8|4@1+ (1,0) [0|15] "" XXX
 SG_ Checksumme_ADR_2 : 0|8@1+ (1,0) [0|0] "" XXX

BO_ 1324 ADR_1: 8 XXX
 SG_ Checksumme_ADR_1 : 56|8@1+ (1,0) [0|0] "" XXX
 SG_ Frei_ADR_1_5 : 52|4@1+ (1,0) [0|0] "" XXX
 SG_ Zeitluecke_gemessen : 48|4@1+ (1,0) [0|15] "" XXX
 SG_ Fehlerspeichereintrag_ADR : 47|1@1+ (1,0) [0|0] "" XXX
 SG_ Reserviert_ADR_1_1 : 40|7@1+ (1,0) [0|0] "" XXX
 SG_ Anzeige_Sensor_blind : 39|1@1+ (1,0) [0|0] "" XXX
 SG_ Ansteuerung_optischer_Fahrerhin : 38|1@1+ (1,0) [0|0] "" XXX
 SG_ Ansteuerung_Gong_2 : 37|1@1+ (1,0) [0|0] "" XXX
 SG_ Ansteuerung_Gong_1 : 36|1@1+ (1,0) [0|0] "" XXX
 SG_ Schaltaufforderung : 34|2@1+ (1,0) [0|0] "" XXX
 SG_ Anzeige_Prioritaet : 33|1@1+ (1,0) [0|0] "" XXX
 SG_ Anzeige_Zeitluecke : 32|1@1+ (1,0) [0|0] "" XXX
 SG_ Wunschgeschwindigkeit : 24|8@1+ (1,0) [0|254] "km/h" XXX
 SG_ Objekt_erfasst : 22|2@1+ (1,0) [0|0] "" XXX
 SG_ Gesetzte_Zeitluecke__ADR_1_ : 18|4@1+ (1,0) [0|15] "" XXX
 SG_ Synchronisation_Bremsbooster : 17|1@1+ (1,0) [0|0] "" XXX
 SG_ Momentenanforderung_Freigabe : 16|1@1+ (1,0) [0|0] "" XXX
 SG_ Verhinderung_Schubabschaltung : 15|1@1+ (1,0) [0|0] "" XXX
 SG_ Status_ADR_1 : 13|2@1+ (1,0) [0|0] "" XXX
 SG_ Fehler_ADR_1 : 12|1@1+ (1,0) [0|0] "" XXX
 SG_ Zaehler_ADR_1 : 8|4@1+ (1,0) [0|15] "" XXX
 SG_ Momentenanforderung_ADR : 0|8@1+ (0.39,0) [0|99] "MDI" XXX

BO_ 210 PQ_HCA: 8 XXX
 SG_ HCA_Status : 15|4@0+ (1,0) [0|15] "" XXX
 SG_ LM_Offset : 16|15@1+ (0.03052,0) [0|300] "nm" XXX
 SG_ LM_Offsign : 31|1@0+ (1,0) [0|1] "" XXX
 SG_ Vib_Amp : 36|4@1+ (0.5,0) [0|7.5] "Nm" XXX
 SG_ Vib_Freq : 32|4@1+ (4,0) [0|60] "Hz" XXX
 SG_ COUNTER : 8|4@1+ (1,0) [0|15] "" XXX
 SG_ PQ_HCA_CHECKSUM : 0|8@1+ (1,0) [0|15] "" XXX

BO_ 1490 VIN_1: 8 XXX

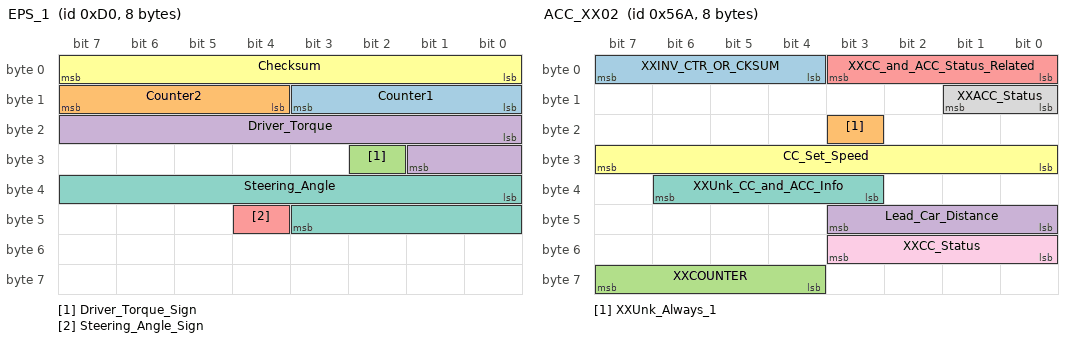
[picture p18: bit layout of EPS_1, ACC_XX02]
BO_ 208 EPS_1: 8 XXX
 SG_ Counter1 : 8|4@1+ (1,0) [0|15] "" XXX
 SG_ Counter2 : 15|4@0+ (1,0) [0|15] "" XXX
 SG_ Driver_Torque_Sign : 26|1@1+ (1,0) [0|1] "" XXX
 SG_ Driver_Torque : 16|10@1+ (1,0) [0|1023] "" XXX
 SG_ Steering_Angle_Sign : 44|1@0+ (1,0) [0|1] "" XXX
 SG_ Checksum : 0|8@1+ (1,0) [0|255] "" XXX
 SG_ Steering_Angle : 32|12@1+ (0.15,0) [0|615] "" XXX

BO_ 1550 Einheiten_1: 2 XXX
 SG_ MFA_v_Signal_02 : 0|1@1+ (1,0) [0|1] "" XXX

BO_ 872 ACC_XX01: 8 XXX
 SG_ XXAccelValue : 24|10@1+ (1,0) [0|255] "" XXX
 SG_ XXDecelGradient : 40|8@1+ (1,0) [0|255] "" XXX
 SG_ XXAccelGradient : 48|8@1+ (1,0) [0|255] "" XXX

BO_ 1386 ACC_XX02: 8 XXX
 SG_ XXINV_CTR_OR_CKSUM : 4|4@1+ (1,0) [0|15] "" XXX
 SG_ XXUnk_Always_1 : 19|1@0+ (1,0) [0|1] "" XXX
 SG_ XXCOUNTER : 60|4@1+ (1,0) [0|15] "" XXX
 SG_ Lead_Car_Distance : 40|4@1+ (1,0) [0|15] "" XXX
 SG_ XXCC_and_ACC_Status_Related : 0|4@1+ (1,0) [0|15] "" XXX
 SG_ CC_Set_Speed : 24|8@1+ (1,0) [0|255] "km/h" XXX
 SG_ XXUnk_CC_and_ACC_Info : 35|4@1+ (1,0) [0|15] "" XXX
 SG_ XXACC_Status : 8|2@1+ (1,0) [0|3] "" XXX
 SG_ XXCC_Status : 48|4@1+ (1,0) [0|15] "" XXX

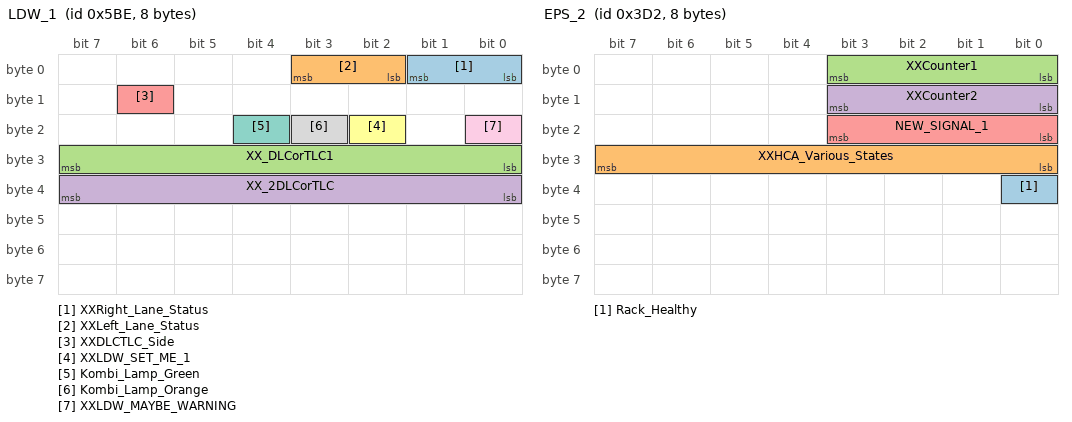
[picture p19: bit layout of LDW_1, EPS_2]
BO_ 1470 LDW_1: 8 XXX
 SG_ XXRight_Lane_Status : 0|2@1+ (1,0) [0|3] "" XXX
 SG_ XXLeft_Lane_Status : 2|2@1+ (1,0) [0|3] "" XXX
 SG_ XX_DLCorTLC1 : 24|8@1+ (1,0) [0|255] "" XXX
 SG_ XX_2DLCorTLC : 32|8@1+ (1,0) [0|15] "" XXX
 SG_ XXDLCTLC_Side : 14|1@0+ (1,0) [0|1] "" XXX
 SG_ XXLDW_SET_ME_1 : 18|1@0+ (1,0) [0|1] "" XXX
 SG_ Kombi_Lamp_Green : 20|1@0+ (1,0) [0|1] "" XXX
 SG_ Kombi_Lamp_Orange : 19|1@0+ (1,0) [0|1] "" XXX
 SG_ XXLDW_MAYBE_WARNING : 16|1@0+ (1,0) [0|1] "" XXX

BO_ 978 EPS_2: 8 XXX
 SG_ Rack_Healthy : 32|1@0+ (1,0) [0|1] "" XXX
 SG_ XXHCA_Various_States : 31|8@0+ (1,0) [0|255] "" XXX
 SG_ XXCounter1 : 0|4@1+ (1,0) [0|15] "" XXX
 SG_ XXCounter2 : 8|4@1+ (1,0) [0|15] "" XXX
 SG_ NEW_SIGNAL_1 : 16|4@1+ (1,0) [0|15] "" XXX

CM_ SG_ 210 LM_Offset "Actually centiNewton-meters for ease of calculation without FP math in Panda";
CM_ SG_ 210 Vib_Amp "Steering wheel haptic, amplitude";
CM_ SG_ 210 Vib_Freq "Steering wheel haptic, frequency";
CM_ SG_ 210 PQ_HCA_CHECKSUM "Bypassing OP CRC code until it understands PQ XOR";
CM_ SG_ 1550 MFA_v_Signal_02 "0=km/h, 1=mph";
CM_ SG_ 1386 XXCC_and_ACC_Status_Related "Looks almost like crude accel/decel, perhaps accel and overrun";
CM_ SG_ 1386 CC_Set_Speed "255=unset, both CC and ACC";
CM_ SG_ 1386 XXACC_Status "ACC only, probably reflects radar control status";
CM_ SG_ 1386 XXCC_Status "CC only, probably reflects ECU control status";
